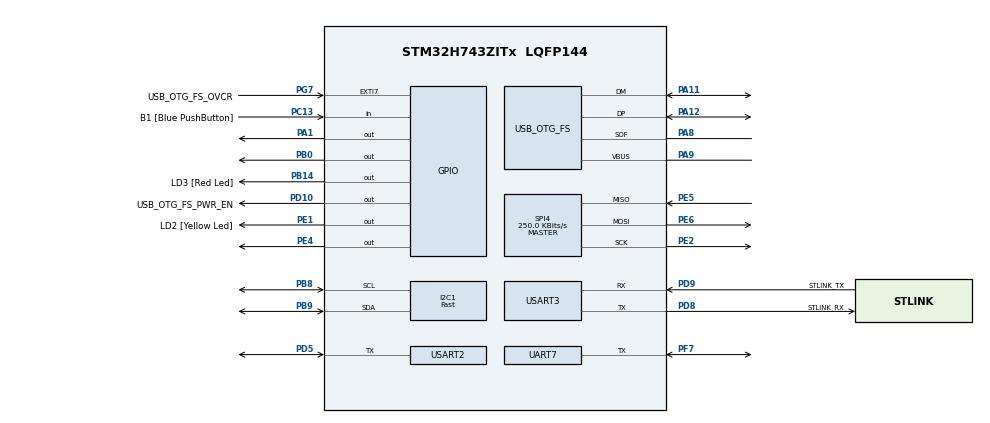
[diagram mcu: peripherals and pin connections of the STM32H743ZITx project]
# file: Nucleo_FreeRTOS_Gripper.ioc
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Dma.I2C1_RX.0.Direction=DMA_PERIPH_TO_MEMORY
Dma.I2C1_RX.0.EventEnable=DISABLE
Dma.I2C1_RX.0.FIFOMode=DMA_FIFOMODE_ENABLE
Dma.I2C1_RX.0.FIFOThreshold=DMA_FIFO_THRESHOLD_FULL
Dma.I2C1_RX.0.Instance=DMA1_Stream0
Dma.I2C1_RX.0.MemBurst=DMA_MBURST_INC16
Dma.I2C1_RX.0.MemDataAlignment=DMA_MDATAALIGN_BYTE
Dma.I2C1_RX.0.MemInc=DMA_MINC_ENABLE
Dma.I2C1_RX.0.Mode=DMA_NORMAL
Dma.I2C1_RX.0.PeriphBurst=DMA_PBURST_SINGLE
Dma.I2C1_RX.0.PeriphDataAlignment=DMA_PDATAALIGN_BYTE
Dma.I2C1_RX.0.PeriphInc=DMA_PINC_DISABLE
Dma.I2C1_RX.0.Polarity=HAL_DMAMUX_REQ_GEN_RISING
Dma.I2C1_RX.0.Priority=DMA_PRIORITY_HIGH
Dma.I2C1_RX.0.RequestNumber=1
Dma.I2C1_RX.0.SignalID=NONE
Dma.I2C1_RX.0.SyncEnable=DISABLE
Dma.I2C1_RX.0.SyncPolarity=HAL_DMAMUX_SYNC_NO_EVENT
Dma.I2C1_RX.0.SyncRequestNumber=1
Dma.I2C1_RX.0.SyncSignalID=NONE
Dma.Request0=I2C1_RX
FREERTOS.Tasks01=ControlTask,24,128,StartControlTask,Default,NULL,Dynamic,NULL,NULL;CommBoard,32,128,StartCommBoard,Default,NULL,Dynamic,NULL,NULL;SensorRead,8,128,StartSensorRead,Default,NULL,Dynamic,NULL,NULL;Safety,8,128,StartSafety,Default,NULL,Dynamic,NULL,NULL
I2C1.CustomTiming=Enabled
I2C1.I2C_Speed_Mode=I2C_Fast
I2C1.OwnAddress=0x5
I2C1.Timing=0x00602173
Mcu.Family=STM32H7
Mcu.Name=STM32H743ZITx
Mcu.Package=LQFP144
NVIC.DMA1_Stream0_IRQn=true\:0\:0\:false\:false\:true\:true\:false\:true
NVIC.PriorityGroup=NVIC_PRIORITYGROUP_4
NVIC.TIM6_DAC_IRQn=true\:0\:0\:false\:false\:true\:false\:false\:true
NVIC.TimeBase=TIM6_DAC_IRQn
NVIC.TimeBaseIP=TIM6
PA1.Signal=GPIO_Output
PA11.Mode=Device_Only
PA11.Signal=USB_OTG_FS_DM
PA12.Mode=Device_Only
PA12.Signal=USB_OTG_FS_DP
PA7.Signal=ETH_CRS_DV
PA8.Mode=Activate_SOF_FS
PA8.Signal=USB_OTG_FS_SOF
PA9.Mode=Activate_VBUS
PA9.Signal=USB_OTG_FS_VBUS
PB0.Signal=GPIO_Output
PB13.Signal=ETH_TXD1
PB14.GPIO_Label=LD3 [Red Led]
PB14.Signal=GPIO_Output
PB8.Mode=I2C
PB8.Signal=I2C1_SCL
PB9.Mode=I2C
PB9.Signal=I2C1_SDA
PC1.Signal=ETH_MDC
PC13.GPIO_Label=B1 [Blue PushButton]
PC13.Signal=GPIO_Input
PC14-OSC32_IN\ (OSC32_IN).Mode=LSE-External-Oscillator
PC14-OSC32_IN\ (OSC32_IN).Signal=RCC_OSC32_IN
PC15-OSC32_OUT\ (OSC32_OUT).Mode=LSE-External-Oscillator
PC15-OSC32_OUT\ (OSC32_OUT).Signal=RCC_OSC32_OUT
PC4.Signal=ETH_RXD0
PC5.Signal=ETH_RXD1
PD10.GPIO_Label=USB_OTG_FS_PWR_EN
PD10.Signal=GPIO_Output
PD5.Mode=Half_duplex(single_wire_mode)
PD5.Signal=USART2_TX
PD8.GPIO_Label=STLINK_RX
PD8.Mode=Asynchronous
PD8.Signal=USART3_TX
PD9.GPIO_Label=STLINK_TX
PD9.Mode=Asynchronous
PD9.Signal=USART3_RX
PE1.GPIO_Label=LD2 [Yellow Led]
PE1.Signal=GPIO_Output
PE2.Mode=Full_Duplex_Master
PE2.Signal=SPI4_SCK
PE4.Signal=GPIO_Output
PE5.Mode=Full_Duplex_Master
PE5.Signal=SPI4_MISO
PE6.Mode=Full_Duplex_Master
PE6.Signal=SPI4_MOSI
PF7.Mode=Half_duplex(single_wire_mode)
PF7.Signal=UART7_TX
PG11.Signal=ETH_TX_EN
PG13.Signal=ETH_TXD0
PG7.GPIO_Label=USB_OTG_FS_OVCR
PG7.Signal=GPXTI7
PH0-OSC_IN\ (PH0).Mode=HSE-External-Clock-Source
PH0-OSC_IN\ (PH0).Signal=RCC_OSC_IN
PH1-OSC_OUT\ (PH1).Signal=RCC_OSC_OUT
ProjectManager.HeapSize=0x200
ProjectManager.StackSize=0x400
ProjectManager.TargetToolchain=STM32CubeIDE
RCC.ADCFreq_Value=16125000
RCC.APB1Freq_Value=64000000
RCC.APB2Freq_Value=64000000
RCC.APB3Freq_Value=64000000
RCC.APB4Freq_Value=64000000
RCC.CortexFreq_Value=64000000
RCC.DIVM1=1
RCC.DIVN1=24
RCC.DIVQ1=4
RCC.HCLKFreq_Value=64000000
RCC.HSE_VALUE=8000000
RCC.PLLFRACN=0
RCC.SYSCLKFreq_VALUE=64000000
RCC.USBFreq_Value=48000000
SPI4.BaudRatePrescaler=SPI_BAUDRATEPRESCALER_256
SPI4.CLKPhase=SPI_PHASE_2EDGE
SPI4.CLKPolarity=SPI_POLARITY_HIGH
SPI4.CalculateBaudRate=250.0 KBits/s
SPI4.DataSize=SPI_DATASIZE_8BIT
SPI4.Direction=SPI_DIRECTION_2LINES
SPI4.Mode=SPI_MODE_MASTER
SPI4.NSSPMode=SPI_NSS_PULSE_DISABLE
SPI4.VirtualType=VM_MASTER
UART7.BaudRate=1000000
USART2.BaudRate=1000000
USART2.VirtualMode-Half_duplex(single_wire_mode)=VM_ASYNC
USART3.VirtualMode-Asynchronous=VM_ASYNC
USB_OTG_FS.VirtualMode=Device_Only
VP_FREERTOS_VS_CMSIS_V2.Mode=CMSIS_V2
VP_SYS_VS_tim6.Mode=TIM6
board=NUCLEO-H743ZI2

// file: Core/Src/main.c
/* USER CODE BEGIN Header */
/**
  ******************************************************************************
  * @file           : main.c
  * @brief          : Main program body
  ******************************************************************************
  * @attention
  *
  * <h2><center>&copy; Copyright (c) 2020 STMicroelectronics.
  * All rights reserved.</center></h2>
  *
  * This software component is licensed by ST under BSD 3-Clause license,
  * the "License"; You may not use this file except in compliance with the
  * License. You may obtain a copy of the License at:
  *                        opensource.org/licenses/BSD-3-Clause
  *
  ******************************************************************************
  */
/* USER CODE END Header */
#include "main.h"
#include "cmsis_os.h"

/* USER CODE BEGIN Includes */

#include<stdio.h>
#include <stdbool.h>

/* USER CODE END Includes */

/* USER CODE BEGIN PTD */

// Adress to nucleo board
#define NUCLEO_ADDRESS "0x5"

// The numbers of sensors
#define NUMBER_OF_MOTORS 8
#define NUMBER_OF_PROXIMITY_SENSORS 7
#define NUMBER_OF_MOUSE_SESNORS 4

/* USER CODE END PTD */

I2C_HandleTypeDef hi2c1;
DMA_HandleTypeDef hdma_i2c1_rx;

SPI_HandleTypeDef hspi4;

UART_HandleTypeDef huart7;
UART_HandleTypeDef huart2;
UART_HandleTypeDef huart3;

PCD_HandleTypeDef hpcd_USB_OTG_FS;

/* Definitions for ControlTask */
osThreadId_t ControlTaskHandle;
const osThreadAttr_t ControlTask_attributes = {
  .name = "ControlTask",
  .priority = (osPriority_t) osPriorityNormal,
  .stack_size = 128 * 4
};
/* Definitions for CommBoard */
osThreadId_t CommBoardHandle;
const osThreadAttr_t CommBoard_attributes = {
  .name = "CommBoard",
  .priority = (osPriority_t) osPriorityAboveNormal,
  .stack_size = 128 * 4
};
/* Definitions for SensorRead */
osThreadId_t SensorReadHandle;
const osThreadAttr_t SensorRead_attributes = {
  .name = "SensorRead",
  .priority = (osPriority_t) osPriorityLow,
  .stack_size = 128 * 4
};
/* Definitions for Safety */
osThreadId_t SafetyHandle;
const osThreadAttr_t Safety_attributes = {
  .name = "Safety",
  .priority = (osPriority_t) osPriorityLow,
  .stack_size = 128 * 4
};
/* USER CODE BEGIN PV */

const unsigned short firmware_length = 4094;

const uint8_t firmware_data[] = {    // SROM 0x04
0x01, 0x04, 0x8e, 0x96, 0x6e, 0x77, 0x3e, 0xfe, 0x7e, 0x5f, 0x1d, 0xb8, 0xf2, 0x66, 0x4e,
0xff, 0x5d, 0x19, 0xb0, 0xc2, 0x04, 0x69, 0x54, 0x2a, 0xd6, 0x2e, 0xbf, 0xdd, 0x19, 0xb0,
0xc3, 0xe5, 0x29, 0xb1, 0xe0, 0x23, 0xa5, 0xa9, 0xb1, 0xc1, 0x00, 0x82, 0x67, 0x4c, 0x1a,
0x97, 0x8d, 0x79, 0x51, 0x20, 0xc7, 0x06, 0x8e, 0x7c, 0x7c, 0x7a, 0x76, 0x4f, 0xfd, 0x59,
0x30, 0xe2, 0x46, 0x0e, 0x9e, 0xbe, 0xdf, 0x1d, 0x99, 0x91, 0xa0, 0xa5, 0xa1, 0xa9, 0xd0,
0x22, 0xc6, 0xef, 0x5c, 0x1b, 0x95, 0x89, 0x90, 0xa2, 0xa7, 0xcc, 0xfb, 0x55, 0x28, 0xb3,
0xe4, 0x4a, 0xf7, 0x6c, 0x3b, 0xf4, 0x6a, 0x56, 0x2e, 0xde, 0x1f, 0x9d, 0xb8, 0xd3, 0x05,
0x88, 0x92, 0xa6, 0xce, 0x1e, 0xbe, 0xdf, 0x1d, 0x99, 0xb0, 0xe2, 0x46, 0xef, 0x5c, 0x07,
0x11, 0x5d, 0x98, 0x0b, 0x9d, 0x94, 0x97, 0xee, 0x4e, 0x45, 0x33, 0x6b, 0x44, 0xc7, 0x29,
0x56, 0x27, 0x30, 0xc6, 0xa7, 0xd5, 0xf2, 0x56, 0xdf, 0xb4, 0x38, 0x62, 0xcb, 0xa0, 0xb6,
0xe3, 0x0f, 0x84, 0x06, 0x24, 0x05, 0x65, 0x6f, 0x76, 0x89, 0xb5, 0x77, 0x41, 0x27, 0x82,
0x66, 0x65, 0x82, 0xcc, 0xd5, 0xe6, 0x20, 0xd5, 0x27, 0x17, 0xc5, 0xf8, 0x03, 0x23, 0x7c,
0x5f, 0x64, 0xa5, 0x1d, 0xc1, 0xd6, 0x36, 0xcb, 0x4c, 0xd4, 0xdb, 0x66, 0xd7, 0x8b, 0xb1,
0x99, 0x7e, 0x6f, 0x4c, 0x36, 0x40, 0x06, 0xd6, 0xeb, 0xd7, 0xa2, 0xe4, 0xf4, 0x95, 0x51,
0x5a, 0x54, 0x96, 0xd5, 0x53, 0x44, 0xd7, 0x8c, 0xe0, 0xb9, 0x40, 0x68, 0xd2, 0x18, 0xe9,
0xdd, 0x9a, 0x23, 0x92, 0x48, 0xee, 0x7f, 0x43, 0xaf, 0xea, 0x77, 0x38, 0x84, 0x8c, 0x0a,
0x72, 0xaf, 0x69, 0xf8, 0xdd, 0xf1, 0x24, 0x83, 0xa3, 0xf8, 0x4a, 0xbf, 0xf5, 0x94, 0x13,
0xdb, 0xbb, 0xd8, 0xb4, 0xb3, 0xa0, 0xfb, 0x45, 0x50, 0x60, 0x30, 0x59, 0x12, 0x31, 0x71,
0xa2, 0xd3, 0x13, 0xe7, 0xfa, 0xe7, 0xce, 0x0f, 0x63, 0x15, 0x0b, 0x6b, 0x94, 0xbb, 0x37,
0x83, 0x26, 0x05, 0x9d, 0xfb, 0x46, 0x92, 0xfc, 0x0a, 0x15, 0xd1, 0x0d, 0x73, 0x92, 0xd6,
0x8c, 0x1b, 0x8c, 0xb8, 0x55, 0x8a, 0xce, 0xbd, 0xfe, 0x8e, 0xfc, 0xed, 0x09, 0x12, 0x83,
0x91, 0x82, 0x51, 0x31, 0x23, 0xfb, 0xb4, 0x0c, 0x76, 0xad, 0x7c, 0xd9, 0xb4, 0x4b, 0xb2,
0x67, 0x14, 0x09, 0x9c, 0x7f, 0x0c, 0x18, 0xba, 0x3b, 0xd6, 0x8e, 0x14, 0x2a, 0xe4, 0x1b,
0x52, 0x9f, 0x2b, 0x7d, 0xe1, 0xfb, 0x6a, 0x33, 0x02, 0xfa, 0xac, 0x5a, 0xf2, 0x3e, 0x88,
0x7e, 0xae, 0xd1, 0xf3, 0x78, 0xe8, 0x05, 0xd1, 0xe3, 0xdc, 0x21, 0xf6, 0xe1, 0x9a, 0xbd,
0x17, 0x0e, 0xd9, 0x46, 0x9b, 0x88, 0x03, 0xea, 0xf6, 0x66, 0xbe, 0x0e, 0x1b, 0x50, 0x49,
0x96, 0x40, 0x97, 0xf1, 0xf1, 0xe4, 0x80, 0xa6, 0x6e, 0xe8, 0x77, 0x34, 0xbf, 0x29, 0x40,
0x44, 0xc2, 0xff, 0x4e, 0x98, 0xd3, 0x9c, 0xa3, 0x32, 0x2b, 0x76, 0x51, 0x04, 0x09, 0xe7,
0xa9, 0xd1, 0xa6, 0x32, 0xb1, 0x23, 0x53, 0xe2, 0x47, 0xab, 0xd6, 0xf5, 0x69, 0x5c, 0x3e,
0x5f, 0xfa, 0xae, 0x45, 0x20, 0xe5, 0xd2, 0x44, 0xff, 0x39, 0x32, 0x6d, 0xfd, 0x27, 0x57,
0x5c, 0xfd, 0xf0, 0xde, 0xc1, 0xb5, 0x99, 0xe5, 0xf5, 0x1c, 0x77, 0x01, 0x75, 0xc5, 0x6d,
0x58, 0x92, 0xf2, 0xb2, 0x47, 0x00, 0x01, 0x26, 0x96, 0x7a, 0x30, 0xff, 0xb7, 0xf0, 0xef,
0x77, 0xc1, 0x8a, 0x5d, 0xdc, 0xc0, 0xd1, 0x29, 0x30, 0x1e, 0x77, 0x38, 0x7a, 0x94, 0xf1,
0xb8, 0x7a, 0x7e, 0xef, 0xa4, 0xd1, 0xac, 0x31, 0x4a, 0xf2, 0x5d, 0x64, 0x3d, 0xb2, 0xe2,
0xf0, 0x08, 0x99, 0xfc, 0x70, 0xee, 0x24, 0xa7, 0x7e, 0xee, 0x1e, 0x20, 0x69, 0x7d, 0x44,
0xbf, 0x87, 0x42, 0xdf, 0x88, 0x3b, 0x0c, 0xda, 0x42, 0xc9, 0x04, 0xf9, 0x45, 0x50, 0xfc,
0x83, 0x8f, 0x11, 0x6a, 0x72, 0xbc, 0x99, 0x95, 0xf0, 0xac, 0x3d, 0xa7, 0x3b, 0xcd, 0x1c,
0xe2, 0x88, 0x79, 0x37, 0x11, 0x5f, 0x39, 0x89, 0x95, 0x0a, 0x16, 0x84, 0x7a, 0xf6, 0x8a,
0xa4, 0x28, 0xe4, 0xed, 0x83, 0x80, 0x3b, 0xb1, 0x23, 0xa5, 0x03, 0x10, 0xf4, 0x66, 0xea,
0xbb, 0x0c, 0x0f, 0xc5, 0xec, 0x6c, 0x69, 0xc5, 0xd3, 0x24, 0xab, 0xd4, 0x2a, 0xb7, 0x99,
0x88, 0x76, 0x08, 0xa0, 0xa8, 0x95, 0x7c, 0xd8, 0x38, 0x6d, 0xcd, 0x59, 0x02, 0x51, 0x4b,
0xf1, 0xb5, 0x2b, 0x50, 0xe3, 0xb6, 0xbd, 0xd0, 0x72, 0xcf, 0x9e, 0xfd, 0x6e, 0xbb, 0x44,
0xc8, 0x24, 0x8a, 0x77, 0x18, 0x8a, 0x13, 0x06, 0xef, 0x97, 0x7d, 0xfa, 0x81, 0xf0, 0x31,
0xe6, 0xfa, 0x77, 0xed, 0x31, 0x06, 0x31, 0x5b, 0x54, 0x8a, 0x9f, 0x30, 0x68, 0xdb, 0xe2,
0x40, 0xf8, 0x4e, 0x73, 0xfa, 0xab, 0x74, 0x8b, 0x10, 0x58, 0x13, 0xdc, 0xd2, 0xe6, 0x78,
0xd1, 0x32, 0x2e, 0x8a, 0x9f, 0x2c, 0x58, 0x06, 0x48, 0x27, 0xc5, 0xa9, 0x5e, 0x81, 0x47,
0x89, 0x46, 0x21, 0x91, 0x03, 0x70, 0xa4, 0x3e, 0x88, 0x9c, 0xda, 0x33, 0x0a, 0xce, 0xbc,
0x8b, 0x8e, 0xcf, 0x9f, 0xd3, 0x71, 0x80, 0x43, 0xcf, 0x6b, 0xa9, 0x51, 0x83, 0x76, 0x30,
0x82, 0xc5, 0x6a, 0x85, 0x39, 0x11, 0x50, 0x1a, 0x82, 0xdc, 0x1e, 0x1c, 0xd5, 0x7d, 0xa9,
0x71, 0x99, 0x33, 0x47, 0x19, 0x97, 0xb3, 0x5a, 0xb1, 0xdf, 0xed, 0xa4, 0xf2, 0xe6, 0x26,
0x84, 0xa2, 0x28, 0x9a, 0x9e, 0xdf, 0xa6, 0x6a, 0xf4, 0xd6, 0xfc, 0x2e, 0x5b, 0x9d, 0x1a,
0x2a, 0x27, 0x68, 0xfb, 0xc1, 0x83, 0x21, 0x4b, 0x90, 0xe0, 0x36, 0xdd, 0x5b, 0x31, 0x42,
0x55, 0xa0, 0x13, 0xf7, 0xd0, 0x89, 0x53, 0x71, 0x99, 0x57, 0x09, 0x29, 0xc5, 0xf3, 0x21,
0xf8, 0x37, 0x2f, 0x40, 0xf3, 0xd4, 0xaf, 0x16, 0x08, 0x36, 0x02, 0xfc, 0x77, 0xc5, 0x8b,
0x04, 0x90, 0x56, 0xb9, 0xc9, 0x67, 0x9a, 0x99, 0xe8, 0x00, 0xd3, 0x86, 0xff, 0x97, 0x2d,
0x08, 0xe9, 0xb7, 0xb3, 0x91, 0xbc, 0xdf, 0x45, 0xc6, 0xed, 0x0f, 0x8c, 0x4c, 0x1e, 0xe6,
0x5b, 0x6e, 0x38, 0x30, 0xe4, 0xaa, 0xe3, 0x95, 0xde, 0xb9, 0xe4, 0x9a, 0xf5, 0xb2, 0x55,
0x9a, 0x87, 0x9b, 0xf6, 0x6a, 0xb2, 0xf2, 0x77, 0x9a, 0x31, 0xf4, 0x7a, 0x31, 0xd1, 0x1d,
0x04, 0xc0, 0x7c, 0x32, 0xa2, 0x9e, 0x9a, 0xf5, 0x62, 0xf8, 0x27, 0x8d, 0xbf, 0x51, 0xff,
0xd3, 0xdf, 0x64, 0x37, 0x3f, 0x2a, 0x6f, 0x76, 0x3a, 0x7d, 0x77, 0x06, 0x9e, 0x77, 0x7f,
0x5e, 0xeb, 0x32, 0x51, 0xf9, 0x16, 0x66, 0x9a, 0x09, 0xf3, 0xb0, 0x08, 0xa4, 0x70, 0x96,
0x46, 0x30, 0xff, 0xda, 0x4f, 0xe9, 0x1b, 0xed, 0x8d, 0xf8, 0x74, 0x1f, 0x31, 0x92, 0xb3,
0x73, 0x17, 0x36, 0xdb, 0x91, 0x30, 0xd6, 0x88, 0x55, 0x6b, 0x34, 0x77, 0x87, 0x7a, 0xe7,
0xee, 0x06, 0xc6, 0x1c, 0x8c, 0x19, 0x0c, 0x48, 0x46, 0x23, 0x5e, 0x9c, 0x07, 0x5c, 0xbf,
0xb4, 0x7e, 0xd6, 0x4f, 0x74, 0x9c, 0xe2, 0xc5, 0x50, 0x8b, 0xc5, 0x8b, 0x15, 0x90, 0x60,
0x62, 0x57, 0x29, 0xd0, 0x13, 0x43, 0xa1, 0x80, 0x88, 0x91, 0x00, 0x44, 0xc7, 0x4d, 0x19,
0x86, 0xcc, 0x2f, 0x2a, 0x75, 0x5a, 0xfc, 0xeb, 0x97, 0x2a, 0x70, 0xe3, 0x78, 0xd8, 0x91,
0xb0, 0x4f, 0x99, 0x07, 0xa3, 0x95, 0xea, 0x24, 0x21, 0xd5, 0xde, 0x51, 0x20, 0x93, 0x27,
0x0a, 0x30, 0x73, 0xa8, 0xff, 0x8a, 0x97, 0xe9, 0xa7, 0x6a, 0x8e, 0x0d, 0xe8, 0xf0, 0xdf,
0xec, 0xea, 0xb4, 0x6c, 0x1d, 0x39, 0x2a, 0x62, 0x2d, 0x3d, 0x5a, 0x8b, 0x65, 0xf8, 0x90,
0x05, 0x2e, 0x7e, 0x91, 0x2c, 0x78, 0xef, 0x8e, 0x7a, 0xc1, 0x2f, 0xac, 0x78, 0xee, 0xaf,
0x28, 0x45, 0x06, 0x4c, 0x26, 0xaf, 0x3b, 0xa2, 0xdb, 0xa3, 0x93, 0x06, 0xb5, 0x3c, 0xa5,
0xd8, 0xee, 0x8f, 0xaf, 0x25, 0xcc, 0x3f, 0x85, 0x68, 0x48, 0xa9, 0x62, 0xcc, 0x97, 0x8f,
0x7f, 0x2a, 0xea, 0xe0, 0x15, 0x0a, 0xad, 0x62, 0x07, 0xbd, 0x45, 0xf8, 0x41, 0xd8, 0x36,
0xcb, 0x4c, 0xdb, 0x6e, 0xe6, 0x3a, 0xe7, 0xda, 0x15, 0xe9, 0x29, 0x1e, 0x12, 0x10, 0xa0,
0x14, 0x2c, 0x0e, 0x3d, 0xf4, 0xbf, 0x39, 0x41, 0x92, 0x75, 0x0b, 0x25, 0x7b, 0xa3, 0xce,
0x39, 0x9c, 0x15, 0x64, 0xc8, 0xfa, 0x3d, 0xef, 0x73, 0x27, 0xfe, 0x26, 0x2e, 0xce, 0xda,
0x6e, 0xfd, 0x71, 0x8e, 0xdd, 0xfe, 0x76, 0xee, 0xdc, 0x12, 0x5c, 0x02, 0xc5, 0x3a, 0x4e,
0x4e, 0x4f, 0xbf, 0xca, 0x40, 0x15, 0xc7, 0x6e, 0x8d, 0x41, 0xf1, 0x10, 0xe0, 0x4f, 0x7e,
0x97, 0x7f, 0x1c, 0xae, 0x47, 0x8e, 0x6b, 0xb1, 0x25, 0x31, 0xb0, 0x73, 0xc7, 0x1b, 0x97,
0x79, 0xf9, 0x80, 0xd3, 0x66, 0x22, 0x30, 0x07, 0x74, 0x1e, 0xe4, 0xd0, 0x80, 0x21, 0xd6,
0xee, 0x6b, 0x6c, 0x4f, 0xbf, 0xf5, 0xb7, 0xd9, 0x09, 0x87, 0x2f, 0xa9, 0x14, 0xbe, 0x27,
0xd9, 0x72, 0x50, 0x01, 0xd4, 0x13, 0x73, 0xa6, 0xa7, 0x51, 0x02, 0x75, 0x25, 0xe1, 0xb3,
0x45, 0x34, 0x7d, 0xa8, 0x8e, 0xeb, 0xf3, 0x16, 0x49, 0xcb, 0x4f, 0x8c, 0xa1, 0xb9, 0x36,
0x85, 0x39, 0x75, 0x5d, 0x08, 0x00, 0xae, 0xeb, 0xf6, 0xea, 0xd7, 0x13, 0x3a, 0x21, 0x5a,
0x5f, 0x30, 0x84, 0x52, 0x26, 0x95, 0xc9, 0x14, 0xf2, 0x57, 0x55, 0x6b, 0xb1, 0x10, 0xc2,
0xe1, 0xbd, 0x3b, 0x51, 0xc0, 0xb7, 0x55, 0x4c, 0x71, 0x12, 0x26, 0xc7, 0x0d, 0xf9, 0x51,
0xa4, 0x38, 0x02, 0x05, 0x7f, 0xb8, 0xf1, 0x72, 0x4b, 0xbf, 0x71, 0x89, 0x14, 0xf3, 0x77,
0x38, 0xd9, 0x71, 0x24, 0xf3, 0x00, 0x11, 0xa1, 0xd8, 0xd4, 0x69, 0x27, 0x08, 0x37, 0x35,
0xc9, 0x11, 0x9d, 0x90, 0x1c, 0x0e, 0xe7, 0x1c, 0xff, 0x2d, 0x1e, 0xe8, 0x92, 0xe1, 0x18,
0x10, 0x95, 0x7c, 0xe0, 0x80, 0xf4, 0x96, 0x43, 0x21, 0xf9, 0x75, 0x21, 0x64, 0x38, 0xdd,
0x9f, 0x1e, 0x95, 0x16, 0xda, 0x56, 0x1d, 0x4f, 0x9a, 0x53, 0xb2, 0xe2, 0xe4, 0x18, 0xcb,
0x6b, 0x1a, 0x65, 0xeb, 0x56, 0xc6, 0x3b, 0xe5, 0xfe, 0xd8, 0x26, 0x3f, 0x3a, 0x84, 0x59,
0x72, 0x66, 0xa2, 0xf3, 0x75, 0xff, 0xfb, 0x60, 0xb3, 0x22, 0xad, 0x3f, 0x2d, 0x6b, 0xf9,
0xeb, 0xea, 0x05, 0x7c, 0xd8, 0x8f, 0x6d, 0x2c, 0x98, 0x9e, 0x2b, 0x93, 0xf1, 0x5e, 0x46,
0xf0, 0x87, 0x49, 0x29, 0x73, 0x68, 0xd7, 0x7f, 0xf9, 0xf0, 0xe5, 0x7d, 0xdb, 0x1d, 0x75,
0x19, 0xf3, 0xc4, 0x58, 0x9b, 0x17, 0x88, 0xa8, 0x92, 0xe0, 0xbe, 0xbd, 0x8b, 0x1d, 0x8d,
0x9f, 0x56, 0x76, 0xad, 0xaf, 0x29, 0xe2, 0xd9, 0xd5, 0x52, 0xf6, 0xb5, 0x56, 0x35, 0x57,
0x3a, 0xc8, 0xe1, 0x56, 0x43, 0x19, 0x94, 0xd3, 0x04, 0x9b, 0x6d, 0x35, 0xd8, 0x0b, 0x5f,
0x4d, 0x19, 0x8e, 0xec, 0xfa, 0x64, 0x91, 0x0a, 0x72, 0x20, 0x2b, 0xbc, 0x1a, 0x4a, 0xfe,
0x8b, 0xfd, 0xbb, 0xed, 0x1b, 0x23, 0xea, 0xad, 0x72, 0x82, 0xa1, 0x29, 0x99, 0x71, 0xbd,
0xf0, 0x95, 0xc1, 0x03, 0xdd, 0x7b, 0xc2, 0xb2, 0x3c, 0x28, 0x54, 0xd3, 0x68, 0xa4, 0x72,
0xc8, 0x66, 0x96, 0xe0, 0xd1, 0xd8, 0x7f, 0xf8, 0xd1, 0x26, 0x2b, 0xf7, 0xad, 0xba, 0x55,
0xca, 0x15, 0xb9, 0x32, 0xc3, 0xe5, 0x88, 0x97, 0x8e, 0x5c, 0xfb, 0x92, 0x25, 0x8b, 0xbf,
0xa2, 0x45, 0x55, 0x7a, 0xa7, 0x6f, 0x8b, 0x57, 0x5b, 0xcf, 0x0e, 0xcb, 0x1d, 0xfb, 0x20,
0x82, 0x77, 0xa8, 0x8c, 0xcc, 0x16, 0xce, 0x1d, 0xfa, 0xde, 0xcc, 0x0b, 0x62, 0xfe, 0xcc,
0xe1, 0xb7, 0xf0, 0xc3, 0x81, 0x64, 0x73, 0x40, 0xa0, 0xc2, 0x4d, 0x89, 0x11, 0x75, 0x33,
0x55, 0x33, 0x8d, 0xe8, 0x4a, 0xfd, 0xea, 0x6e, 0x30, 0x0b, 0xd7, 0x31, 0x2c, 0xde, 0x47,
0xe3, 0xbf, 0xf8, 0x55, 0x42, 0xe2, 0x7f, 0x59, 0xe5, 0x17, 0xef, 0x99, 0x34, 0x69, 0x91,
0xb1, 0x23, 0x8e, 0x20, 0x87, 0x2d, 0xa8, 0xfe, 0xd5, 0x8a, 0xf3, 0x84, 0x3a, 0xf0, 0x37,
0xe4, 0x09, 0x00, 0x54, 0xee, 0x67, 0x49, 0x93, 0xe4, 0x81, 0x70, 0xe3, 0x90, 0x4d, 0xef,
0xfe, 0x41, 0xb7, 0x99, 0x7b, 0xc1, 0x83, 0xba, 0x62, 0x12, 0x6f, 0x7d, 0xde, 0x6b, 0xaf,
0xda, 0x16, 0xf9, 0x55, 0x51, 0xee, 0xa6, 0x0c, 0x2b, 0x02, 0xa3, 0xfd, 0x8d, 0xfb, 0x30,
0x17, 0xe4, 0x6f, 0xdf, 0x36, 0x71, 0xc4, 0xca, 0x87, 0x25, 0x48, 0xb0, 0x47, 0xec, 0xea,
0xb4, 0xbf, 0xa5, 0x4d, 0x9b, 0x9f, 0x02, 0x93, 0xc4, 0xe3, 0xe4, 0xe8, 0x42, 0x2d, 0x68,
0x81, 0x15, 0x0a, 0xeb, 0x84, 0x5b, 0xd6, 0xa8, 0x74, 0xfb, 0x7d, 0x1d, 0xcb, 0x2c, 0xda,
0x46, 0x2a, 0x76, 0x62, 0xce, 0xbc, 0x5c, 0x9e, 0x8b, 0xe7, 0xcf, 0xbe, 0x78, 0xf5, 0x7c,
0xeb, 0xb3, 0x3a, 0x9c, 0xaa, 0x6f, 0xcc, 0x72, 0xd1, 0x59, 0xf2, 0x11, 0x23, 0xd6, 0x3f,
0x48, 0xd1, 0xb7, 0xce, 0xb0, 0xbf, 0xcb, 0xea, 0x80, 0xde, 0x57, 0xd4, 0x5e, 0x97, 0x2f,
0x75, 0xd1, 0x50, 0x8e, 0x80, 0x2c, 0x66, 0x79, 0xbf, 0x72, 0x4b, 0xbd, 0x8a, 0x81, 0x6c,
0xd3, 0xe1, 0x01, 0xdc, 0xd2, 0x15, 0x26, 0xc5, 0x36, 0xda, 0x2c, 0x1a, 0xc0, 0x27, 0x94,
0xed, 0xb7, 0x9b, 0x85, 0x0b, 0x5e, 0x80, 0x97, 0xc5, 0xec, 0x4f, 0xec, 0x88, 0x5d, 0x50,
0x07, 0x35, 0x47, 0xdc, 0x0b, 0x3b, 0x3d, 0xdd, 0x60, 0xaf, 0xa8, 0x5d, 0x81, 0x38, 0x24,
0x25, 0x5d, 0x5c, 0x15, 0xd1, 0xde, 0xb3, 0xab, 0xec, 0x05, 0x69, 0xef, 0x83, 0xed, 0x57,
0x54, 0xb8, 0x64, 0x64, 0x11, 0x16, 0x32, 0x69, 0xda, 0x9f, 0x2d, 0x7f, 0x36, 0xbb, 0x44,
0x5a, 0x34, 0xe8, 0x7f, 0xbf, 0x03, 0xeb, 0x00, 0x7f, 0x59, 0x68, 0x22, 0x79, 0xcf, 0x73,
0x6c, 0x2c, 0x29, 0xa7, 0xa1, 0x5f, 0x38, 0xa1, 0x1d, 0xf0, 0x20, 0x53, 0xe0, 0x1a, 0x63,
0x14, 0x58, 0x71, 0x10, 0xaa, 0x08, 0x0c, 0x3e, 0x16, 0x1a, 0x60, 0x22, 0x82, 0x7f, 0xba,
0xa4, 0x43, 0xa0, 0xd0, 0xac, 0x1b, 0xd5, 0x6b, 0x64, 0xb5, 0x14, 0x93, 0x31, 0x9e, 0x53,
0x50, 0xd0, 0x57, 0x66, 0xee, 0x5a, 0x4f, 0xfb, 0x03, 0x2a, 0x69, 0x58, 0x76, 0xf1, 0x83,
0xf7, 0x4e, 0xba, 0x8c, 0x42, 0x06, 0x60, 0x5d, 0x6d, 0xce, 0x60, 0x88, 0xae, 0xa4, 0xc3,
0xf1, 0x03, 0xa5, 0x4b, 0x98, 0xa1, 0xff, 0x67, 0xe1, 0xac, 0xa2, 0xb8, 0x62, 0xd7, 0x6f,
0xa0, 0x31, 0xb4, 0xd2, 0x77, 0xaf, 0x21, 0x10, 0x06, 0xc6, 0x9a, 0xff, 0x1d, 0x09, 0x17,
0x0e, 0x5f, 0xf1, 0xaa, 0x54, 0x34, 0x4b, 0x45, 0x8a, 0x87, 0x63, 0xa6, 0xdc, 0xf9, 0x24,
0x30, 0x67, 0xc6, 0xb2, 0xd6, 0x61, 0x33, 0x69, 0xee, 0x50, 0x61, 0x57, 0x28, 0xe7, 0x7e,
0xee, 0xec, 0x3a, 0x5a, 0x73, 0x4e, 0xa8, 0x8d, 0xe4, 0x18, 0xea, 0xec, 0x41, 0x64, 0xc8,
0xe2, 0xe8, 0x66, 0xb6, 0x2d, 0xb6, 0xfb, 0x6a, 0x6c, 0x16, 0xb3, 0xdd, 0x46, 0x43, 0xb9,
0x73, 0x00, 0x6a, 0x71, 0xed, 0x4e, 0x9d, 0x25, 0x1a, 0xc3, 0x3c, 0x4a, 0x95, 0x15, 0x99,
0x35, 0x81, 0x14, 0x02, 0xd6, 0x98, 0x9b, 0xec, 0xd8, 0x23, 0x3b, 0x84, 0x29, 0xaf, 0x0c,
0x99, 0x83, 0xa6, 0x9a, 0x34, 0x4f, 0xfa, 0xe8, 0xd0, 0x3c, 0x4b, 0xd0, 0xfb, 0xb6, 0x68,
0xb8, 0x9e, 0x8f, 0xcd, 0xf7, 0x60, 0x2d, 0x7a, 0x22, 0xe5, 0x7d, 0xab, 0x65, 0x1b, 0x95,
0xa7, 0xa8, 0x7f, 0xb6, 0x77, 0x47, 0x7b, 0x5f, 0x8b, 0x12, 0x72, 0xd0, 0xd4, 0x91, 0xef,
0xde, 0x19, 0x50, 0x3c, 0xa7, 0x8b, 0xc4, 0xa9, 0xb3, 0x23, 0xcb, 0x76, 0xe6, 0x81, 0xf0,
0xc1, 0x04, 0x8f, 0xa3, 0xb8, 0x54, 0x5b, 0x97, 0xac, 0x19, 0xff, 0x3f, 0x55, 0x27, 0x2f,
0xe0, 0x1d, 0x42, 0x9b, 0x57, 0xfc, 0x4b, 0x4e, 0x0f, 0xce, 0x98, 0xa9, 0x43, 0x57, 0x03,
0xbd, 0xe7, 0xc8, 0x94, 0xdf, 0x6e, 0x36, 0x73, 0x32, 0xb4, 0xef, 0x2e, 0x85, 0x7a, 0x6e,
0xfc, 0x6c, 0x18, 0x82, 0x75, 0x35, 0x90, 0x07, 0xf3, 0xe4, 0x9f, 0x3e, 0xdc, 0x68, 0xf3,
0xb5, 0xf3, 0x19, 0x80, 0x92, 0x06, 0x99, 0xa2, 0xe8, 0x6f, 0xff, 0x2e, 0x7f, 0xae, 0x42,
0xa4, 0x5f, 0xfb, 0xd4, 0x0e, 0x81, 0x2b, 0xc3, 0x04, 0xff, 0x2b, 0xb3, 0x74, 0x4e, 0x36,
0x5b, 0x9c, 0x15, 0x00, 0xc6, 0x47, 0x2b, 0xe8, 0x8b, 0x3d, 0xf1, 0x9c, 0x03, 0x9a, 0x58,
0x7f, 0x9b, 0x9c, 0xbf, 0x85, 0x49, 0x79, 0x35, 0x2e, 0x56, 0x7b, 0x41, 0x14, 0x39, 0x47,
0x83, 0x26, 0xaa, 0x07, 0x89, 0x98, 0x11, 0x1b, 0x86, 0xe7, 0x73, 0x7a, 0xd8, 0x7d, 0x78,
0x61, 0x53, 0xe9, 0x79, 0xf5, 0x36, 0x8d, 0x44, 0x92, 0x84, 0xf9, 0x13, 0x50, 0x58, 0x3b,
0xa4, 0x6a, 0x36, 0x65, 0x49, 0x8e, 0x3c, 0x0e, 0xf1, 0x6f, 0xd2, 0x84, 0xc4, 0x7e, 0x8e,
0x3f, 0x39, 0xae, 0x7c, 0x84, 0xf1, 0x63, 0x37, 0x8e, 0x3c, 0xcc, 0x3e, 0x44, 0x81, 0x45,
0xf1, 0x4b, 0xb9, 0xed, 0x6b, 0x36, 0x5d, 0xbb, 0x20, 0x60, 0x1a, 0x0f, 0xa3, 0xaa, 0x55,
0x77, 0x3a, 0xa9, 0xae, 0x37, 0x4d, 0xba, 0xb8, 0x86, 0x6b, 0xbc, 0x08, 0x50, 0xf6, 0xcc,
0xa4, 0xbd, 0x1d, 0x40, 0x72, 0xa5, 0x86, 0xfa, 0xe2, 0x10, 0xae, 0x3d, 0x58, 0x4b, 0x97,
0xf3, 0x43, 0x74, 0xa9, 0x9e, 0xeb, 0x21, 0xb7, 0x01, 0xa4, 0x86, 0x93, 0x97, 0xee, 0x2f,
0x4f, 0x3b, 0x86, 0xa1, 0x41, 0x6f, 0x41, 0x26, 0x90, 0x78, 0x5c, 0x7f, 0x30, 0x38, 0x4b,
0x3f, 0xaa, 0xec, 0xed, 0x5c, 0x6f, 0x0e, 0xad, 0x43, 0x87, 0xfd, 0x93, 0x35, 0xe6, 0x01,
0xef, 0x41, 0x26, 0x90, 0x99, 0x9e, 0xfb, 0x19, 0x5b, 0xad, 0xd2, 0x91, 0x8a, 0xe0, 0x46,
0xaf, 0x65, 0xfa, 0x4f, 0x84, 0xc1, 0xa1, 0x2d, 0xcf, 0x45, 0x8b, 0xd3, 0x85, 0x50, 0x55,
0x7c, 0xf9, 0x67, 0x88, 0xd4, 0x4e, 0xe9, 0xd7, 0x6b, 0x61, 0x54, 0xa1, 0xa4, 0xa6, 0xa2,
0xc2, 0xbf, 0x30, 0x9c, 0x40, 0x9f, 0x5f, 0xd7, 0x69, 0x2b, 0x24, 0x82, 0x5e, 0xd9, 0xd6,
0xa7, 0x12, 0x54, 0x1a, 0xf7, 0x55, 0x9f, 0x76, 0x50, 0xa9, 0x95, 0x84, 0xe6, 0x6b, 0x6d,
0xb5, 0x96, 0x54, 0xd6, 0xcd, 0xb3, 0xa1, 0x9b, 0x46, 0xa7, 0x94, 0x4d, 0xc4, 0x94, 0xb4,
0x98, 0xe3, 0xe1, 0xe2, 0x34, 0xd5, 0x33, 0x16, 0x07, 0x54, 0xcd, 0xb7, 0x77, 0x53, 0xdb,
0x4f, 0x4d, 0x46, 0x9d, 0xe9, 0xd4, 0x9c, 0x8a, 0x36, 0xb6, 0xb8, 0x38, 0x26, 0x6c, 0x0e,
0xff, 0x9c, 0x1b, 0x43, 0x8b, 0x80, 0xcc, 0xb9, 0x3d, 0xda, 0xc7, 0xf1, 0x8a, 0xf2, 0x6d,
0xb8, 0xd7, 0x74, 0x2f, 0x7e, 0x1e, 0xb7, 0xd3, 0x4a, 0xb4, 0xac, 0xfc, 0x79, 0x48, 0x6c,
0xbc, 0x96, 0xb6, 0x94, 0x46, 0x57, 0x2d, 0xb0, 0xa3, 0xfc, 0x1e, 0xb9, 0x52, 0x60, 0x85,
0x2d, 0x41, 0xd0, 0x43, 0x01, 0x1e, 0x1c, 0xd5, 0x7d, 0xfc, 0xf3, 0x96, 0x0d, 0xc7, 0xcb,
0x2a, 0x29, 0x9a, 0x93, 0xdd, 0x88, 0x2d, 0x37, 0x5d, 0xaa, 0xfb, 0x49, 0x68, 0xa0, 0x9c,
0x50, 0x86, 0x7f, 0x68, 0x56, 0x57, 0xf9, 0x79, 0x18, 0x39, 0xd4, 0xe0, 0x01, 0x84, 0x33,
0x61, 0xca, 0xa5, 0xd2, 0xd6, 0xe4, 0xc9, 0x8a, 0x4a, 0x23, 0x44, 0x4e, 0xbc, 0xf0, 0xdc,
0x24, 0xa1, 0xa0, 0xc4, 0xe2, 0x07, 0x3c, 0x10, 0xc4, 0xb5, 0x25, 0x4b, 0x65, 0x63, 0xf4,
0x80, 0xe7, 0xcf, 0x61, 0xb1, 0x71, 0x82, 0x21, 0x87, 0x2c, 0xf5, 0x91, 0x00, 0x32, 0x0c,
0xec, 0xa9, 0xb5, 0x9a, 0x74, 0x85, 0xe3, 0x36, 0x8f, 0x76, 0x4f, 0x9c, 0x6d, 0xce, 0xbc,
0xad, 0x0a, 0x4b, 0xed, 0x76, 0x04, 0xcb, 0xc3, 0xb9, 0x33, 0x9e, 0x01, 0x93, 0x96, 0x69,
0x7d, 0xc5, 0xa2, 0x45, 0x79, 0x9b, 0x04, 0x5c, 0x84, 0x09, 0xed, 0x88, 0x43, 0xc7, 0xab,
0x93, 0x14, 0x26, 0xa1, 0x40, 0xb5, 0xce, 0x4e, 0xbf, 0x2a, 0x42, 0x85, 0x3e, 0x2c, 0x3b,
0x54, 0xe8, 0x12, 0x1f, 0x0e, 0x97, 0x59, 0xb2, 0x27, 0x89, 0xfa, 0xf2, 0xdf, 0x8e, 0x68,
0x59, 0xdc, 0x06, 0xbc, 0xb6, 0x85, 0x0d, 0x06, 0x22, 0xec, 0xb1, 0xcb, 0xe5, 0x04, 0xe6,
0x3d, 0xb3, 0xb0, 0x41, 0x73, 0x08, 0x3f, 0x3c, 0x58, 0x86, 0x63, 0xeb, 0x50, 0xee, 0x1d,
0x2c, 0x37, 0x74, 0xa9, 0xd3, 0x18, 0xa3, 0x47, 0x6e, 0x93, 0x54, 0xad, 0x0a, 0x5d, 0xb8,
0x2a, 0x55, 0x5d, 0x78, 0xf6, 0xee, 0xbe, 0x8e, 0x3c, 0x76, 0x69, 0xb9, 0x40, 0xc2, 0x34,
0xec, 0x2a, 0xb9, 0xed, 0x7e, 0x20, 0xe4, 0x8d, 0x00, 0x38, 0xc7, 0xe6, 0x8f, 0x44, 0xa8,
0x86, 0xce, 0xeb, 0x2a, 0xe9, 0x90, 0xf1, 0x4c, 0xdf, 0x32, 0xfb, 0x73, 0x1b, 0x6d, 0x92,
0x1e, 0x95, 0xfe, 0xb4, 0xdb, 0x65, 0xdf, 0x4d, 0x23, 0x54, 0x89, 0x48, 0xbf, 0x4a, 0x2e,
0x70, 0xd6, 0xd7, 0x62, 0xb4, 0x33, 0x29, 0xb1, 0x3a, 0x33, 0x4c, 0x23, 0x6d, 0xa6, 0x76,
0xa5, 0x21, 0x63, 0x48, 0xe6, 0x90, 0x5d, 0xed, 0x90, 0x95, 0x0b, 0x7a, 0x84, 0xbe, 0xb8,
0x0d, 0x5e, 0x63, 0x0c, 0x62, 0x26, 0x4c, 0x14, 0x5a, 0xb3, 0xac, 0x23, 0xa4, 0x74, 0xa7,
0x6f, 0x33, 0x30, 0x05, 0x60, 0x01, 0x42, 0xa0, 0x28, 0xb7, 0xee, 0x19, 0x38, 0xf1, 0x64,
0x80, 0x82, 0x43, 0xe1, 0x41, 0x27, 0x1f, 0x1f, 0x90, 0x54, 0x7a, 0xd5, 0x23, 0x2e, 0xd1,
0x3d, 0xcb, 0x28, 0xba, 0x58, 0x7f, 0xdc, 0x7c, 0x91, 0x24, 0xe9, 0x28, 0x51, 0x83, 0x6e,
0xc5, 0x56, 0x21, 0x42, 0xed, 0xa0, 0x56, 0x22, 0xa1, 0x40, 0x80, 0x6b, 0xa8, 0xf7, 0x94,
0xca, 0x13, 0x6b, 0x0c, 0x39, 0xd9, 0xfd, 0xe9, 0xf3, 0x6f, 0xa6, 0x9e, 0xfc, 0x70, 0x8a,
0xb3, 0xbc, 0x59, 0x3c, 0x1e, 0x1d, 0x6c, 0xf9, 0x7c, 0xaf, 0xf9, 0x88, 0x71, 0x95, 0xeb,
0x57, 0x00, 0xbd, 0x9f, 0x8c, 0x4f, 0xe1, 0x24, 0x83, 0xc5, 0x22, 0xea, 0xfd, 0xd3, 0x0c,
0xe2, 0x17, 0x18, 0x7c, 0x6a, 0x4c, 0xde, 0x77, 0xb4, 0x53, 0x9b, 0x4c, 0x81, 0xcd, 0x23,
0x60, 0xaa, 0x0e, 0x25, 0x73, 0x9c, 0x02, 0x79, 0x32, 0x30, 0xdf, 0x74, 0xdf, 0x75, 0x19,
0xf4, 0xa5, 0x14, 0x5c, 0xf7, 0x7a, 0xa8, 0xa5, 0x91, 0x84, 0x7c, 0x60, 0x03, 0x06, 0x3b,
0xcd, 0x50, 0xb6, 0x27, 0x9c, 0xfe, 0xb1, 0xdd, 0xcc, 0xd3, 0xb0, 0x59, 0x24, 0xb2, 0xca,
0xe2, 0x1c, 0x81, 0x22, 0x9d, 0x07, 0x8f, 0x8e, 0xb9, 0xbe, 0x4e, 0xfa, 0xfc, 0x39, 0x65,
0xba, 0xbf, 0x9d, 0x12, 0x37, 0x5e, 0x97, 0x7e, 0xf3, 0x89, 0xf5, 0x5d, 0xf5, 0xe3, 0x09,
0x8c, 0x62, 0xb5, 0x20, 0x9d, 0x0c, 0x53, 0x8a, 0x68, 0x1b, 0xd2, 0x8f, 0x75, 0x17, 0x5d,
0xd4, 0xe5, 0xda, 0x75, 0x62, 0x19, 0x14, 0x6a, 0x26, 0x2d, 0xeb, 0xf8, 0xaf, 0x37, 0xf0,
0x6c, 0xa4, 0x55, 0xb1, 0xbc, 0xe2, 0x33, 0xc0, 0x9a, 0xca, 0xb0, 0x11, 0x49, 0x4f, 0x68,
0x9b, 0x3b, 0x6b, 0x3c, 0xcc, 0x13, 0xf6, 0xc7, 0x85, 0x61, 0x68, 0x42, 0xae, 0xbb, 0xdd,
0xcd, 0x45, 0x16, 0x29, 0x1d, 0xea, 0xdb, 0xc8, 0x03, 0x94, 0x3c, 0xee, 0x4f, 0x82, 0x11,
0xc3, 0xec, 0x28, 0xbd, 0x97, 0x05, 0x99, 0xde, 0xd7, 0xbb, 0x5e, 0x22, 0x1f, 0xd4, 0xeb,
0x64, 0xd9, 0x92, 0xd9, 0x85, 0xb7, 0x6a, 0x05, 0x6a, 0xe4, 0x24, 0x41, 0xf1, 0xcd, 0xf0,
0xd8, 0x3f, 0xf8, 0x9e, 0x0e, 0xcd, 0x0b, 0x7a, 0x70, 0x6b, 0x5a, 0x75, 0x0a, 0x6a, 0x33,
0x88, 0xec, 0x17, 0x75, 0x08, 0x70, 0x10, 0x2f, 0x24, 0xcf, 0xc4, 0xe9, 0x42, 0x00, 0x61,
0x94, 0xca, 0x1f, 0x3a, 0x76, 0x06, 0xfa, 0xd2, 0x48, 0x81, 0xf0, 0x77, 0x60, 0x03, 0x45,
0xd9, 0x61, 0xf4, 0xa4, 0x6f, 0x3d, 0xd9, 0x30, 0xc3, 0x04, 0x6b, 0x54, 0x2a, 0xb7, 0xec,
0x3b, 0xf4, 0x4b, 0xf5, 0x68, 0x52, 0x26, 0xce, 0xff, 0x5d, 0x19, 0x91, 0xa0, 0xa3, 0xa5,
0xa9, 0xb1, 0xe0, 0x23, 0xc4, 0x0a, 0x77, 0x4d, 0xf9, 0x51, 0x20, 0xa3, 0xa5, 0xa9, 0xb1,
0xc1, 0x00, 0x82, 0x86, 0x8e, 0x7f, 0x5d, 0x19, 0x91, 0xa0, 0xa3, 0xc4, 0xeb, 0x54, 0x0b,
0x75, 0x68, 0x52, 0x07, 0x8c, 0x9a, 0x97, 0x8d, 0x79, 0x70, 0x62, 0x46, 0xef, 0x5c, 0x1b,
0x95, 0x89, 0x71, 0x41, 0xe1, 0x21, 0xa1, 0xa1, 0xa1, 0xc0, 0x02, 0x67, 0x4c, 0x1a, 0xb6,
0xcf, 0xfd, 0x78, 0x53, 0x24, 0xab, 0xb5, 0xc9, 0xf1, 0x60, 0x23, 0xa5, 0xc8, 0x12, 0x87,
0x6d, 0x58, 0x13, 0x85, 0x88, 0x92, 0x87, 0x6d, 0x58, 0x32, 0xc7, 0x0c, 0x9a, 0x97, 0xac,
0xda, 0x36, 0xee, 0x5e, 0x3e, 0xdf, 0x1d, 0xb8, 0xf2, 0x66, 0x2f, 0xbd, 0xf8, 0x72, 0x47,
0xed, 0x58, 0x13, 0x85, 0x88, 0x92, 0x87, 0x8c, 0x7b, 0x55, 0x09, 0x90, 0xa2, 0xc6, 0xef,
0x3d, 0xf8, 0x53, 0x24, 0xab, 0xd4, 0x2a, 0xb7, 0xec, 0x5a, 0x36, 0xee, 0x5e, 0x3e, 0xdf,
0x3c, 0xfa, 0x76, 0x4f, 0xfd, 0x59, 0x30, 0xe2, 0x46, 0xef, 0x3d, 0xf8, 0x53, 0x05, 0x69,
0x31, 0xc1, 0x00, 0x82, 0x86, 0x8e, 0x7f, 0x5d, 0x19, 0xb0, 0xe2, 0x27, 0xcc, 0xfb, 0x74,
0x4b, 0x14, 0x8b, 0x94, 0x8b, 0x75, 0x68, 0x33, 0xc5, 0x08, 0x92, 0x87, 0x8c, 0x9a, 0xb6,
0xcf, 0x1c, 0xba, 0xd7, 0x0d, 0x98, 0xb2, 0xe6, 0x2f, 0xdc, 0x1b, 0x95, 0x89, 0x71, 0x60,
0x23, 0xc4, 0x0a, 0x96, 0x8f, 0x9c, 0xba, 0xf6, 0x6e, 0x3f, 0xfc, 0x5b, 0x15, 0xa8, 0xd2,
0x26, 0xaf, 0xbd, 0xf8, 0x72, 0x66, 0x2f, 0xdc, 0x1b, 0xb4, 0xcb, 0x14, 0x8b, 0x94, 0xaa,
0xb7, 0xcd, 0xf9, 0x51, 0x01, 0x80, 0x82, 0x86, 0x6f, 0x3d, 0xd9, 0x30, 0xe2, 0x27, 0xcc,
0xfb, 0x74, 0x4b, 0x14, 0xaa, 0xb7, 0xcd, 0xf9, 0x70, 0x43, 0x04, 0x6b, 0x35, 0xc9, 0xf1,
0x60, 0x23, 0xa5, 0xc8, 0xf3, 0x45, 0x08, 0x92, 0x87, 0x6d, 0x58, 0x32, 0xe6, 0x2f, 0xbd,
0xf8, 0x72, 0x66, 0x4e, 0x1e, 0xbe, 0xfe, 0x7e, 0x7e, 0x7e, 0x5f, 0x1d, 0x99, 0x91, 0xa0,
0xa3, 0xc4, 0x0a, 0x77, 0x4d, 0x18, 0x93, 0xa4, 0xab, 0xd4, 0x0b, 0x75, 0x49, 0x10, 0xa2,
0xc6, 0xef, 0x3d, 0xf8, 0x53, 0x24, 0xab, 0xb5, 0xe8, 0x33, 0xe4, 0x4a, 0x16, 0xae, 0xde,
0x1f, 0xbc, 0xdb, 0x15, 0xa8, 0xb3, 0xc5, 0x08, 0x73, 0x45, 0xe9, 0x31, 0xc1, 0xe1, 0x21,
0xa1, 0xa1, 0xa1, 0xc0, 0x02, 0x86, 0x6f, 0x5c, 0x3a, 0xd7, 0x0d, 0x98, 0x93, 0xa4, 0xca,
0x16, 0xae, 0xde, 0x1f, 0x9d, 0x99, 0xb0, 0xe2, 0x46, 0xef, 0x3d, 0xf8, 0x72, 0x47, 0x0c,
0x9a, 0xb6, 0xcf, 0xfd, 0x59, 0x11, 0xa0, 0xa3, 0xa5, 0xc8, 0xf3, 0x45, 0x08, 0x92, 0x87,
0x6d, 0x39, 0xf0, 0x43, 0x04, 0x8a, 0x96, 0xae, 0xde, 0x3e, 0xdf, 0x1d, 0x99, 0x91, 0xa0,
0xc2, 0x06, 0x6f, 0x3d, 0xf8, 0x72, 0x47, 0x0c, 0x9a, 0x97, 0x8d, 0x98, 0x93, 0x85, 0x88,
0x73, 0x45, 0xe9, 0x31, 0xe0, 0x23, 0xa5, 0xa9, 0xd0, 0x03, 0x84, 0x8a, 0x96, 0xae, 0xde,
0x1f, 0xbc, 0xdb, 0x15, 0xa8, 0xd2, 0x26, 0xce, 0xff, 0x5d, 0x19, 0x91, 0x81, 0x80, 0x82,
0x67, 0x2d, 0xd8, 0x13, 0xa4, 0xab, 0xd4, 0x0b, 0x94, 0xaa, 0xb7, 0xcd, 0xf9, 0x51, 0x20,
0xa3, 0xa5, 0xc8, 0xf3, 0x45, 0xe9, 0x50, 0x22, 0xc6, 0xef, 0x5c, 0x3a, 0xd7, 0x0d, 0x98,
0x93, 0x85, 0x88, 0x73, 0x64, 0x4a, 0xf7, 0x4d, 0xf9, 0x51, 0x20, 0xa3, 0xc4, 0x0a, 0x96,
0xae, 0xde, 0x3e, 0xfe, 0x7e, 0x7e, 0x7e, 0x5f, 0x3c, 0xfa, 0x76, 0x4f, 0xfd, 0x78, 0x72,
0x66, 0x2f, 0xbd, 0xd9, 0x30, 0xc3, 0xe5, 0x48, 0x12, 0x87, 0x8c, 0x7b, 0x55, 0x28, 0xd2,
0x07, 0x8c, 0x9a, 0x97, 0xac, 0xda, 0x17, 0x8d, 0x79, 0x51, 0x20, 0xa3, 0xc4, 0xeb, 0x54,
0x0b, 0x94, 0x8b, 0x94, 0xaa, 0xd6, 0x2e, 0xbf, 0xfc, 0x5b, 0x15, 0xa8, 0xd2, 0x26, 0xaf,
0xdc, 0x1b, 0xb4, 0xea, 0x37, 0xec, 0x3b, 0xf4, 0x6a, 0x37, 0xcd, 0x18, 0x93, 0x85, 0x69,
0x31, 0xc1, 0xe1, 0x40, 0xe3, 0x25, 0xc8, 0x12, 0x87, 0x8c, 0x9a, 0xb6, 0xcf, 0xfd, 0x59,
0x11, 0xa0, 0xc2, 0x06, 0x8e, 0x7f, 0x5d, 0x38, 0xf2, 0x47, 0x0c, 0x7b, 0x74, 0x6a, 0x37,
0xec, 0x5a, 0x36, 0xee, 0x3f, 0xfc, 0x7a, 0x76, 0x4f, 0x1c, 0x9b, 0x95, 0x89, 0x71, 0x41,
0x00, 0x63, 0x44, 0xeb, 0x54, 0x2a, 0xd6, 0x0f, 0x9c, 0xba, 0xd7, 0x0d, 0x98, 0x93, 0x85,
0x69, 0x31, 0xc1, 0x00, 0x82, 0x86, 0x8e, 0x9e, 0xbe, 0xdf, 0x3c, 0xfa, 0x57, 0x2c, 0xda,
0x36, 0xee, 0x3f, 0xfc, 0x5b, 0x15, 0x89, 0x71, 0x41, 0x00, 0x82, 0x86, 0x8e, 0x7f, 0x5d,
0x38, 0xf2, 0x47, 0xed, 0x58, 0x13, 0xa4, 0xca, 0xf7, 0x4d, 0xf9, 0x51, 0x01, 0x80, 0x63,
0x44, 0xeb, 0x54, 0x2a, 0xd6, 0x2e, 0xbf, 0xdd, 0x19, 0x91, 0xa0, 0xa3, 0xa5, 0xa9, 0xb1,
0xe0, 0x42, 0x06, 0x8e, 0x7f, 0x5d, 0x19, 0x91, 0xa0, 0xa3, 0xc4, 0x0a, 0x96, 0x8f, 0x7d,
0x78, 0x72, 0x47, 0x0c, 0x7b, 0x74, 0x6a, 0x56, 0x2e, 0xde, 0x1f, 0xbc, 0xfa, 0x57, 0x0d,
0x79, 0x51, 0x01, 0x61, 0x21, 0xa1, 0xc0, 0xe3, 0x25, 0xa9, 0xb1, 0xc1, 0xe1, 0x40, 0x02,
0x67, 0x4c, 0x1a, 0x97, 0x8d, 0x98, 0x93, 0xa4, 0xab, 0xd4, 0x2a, 0xd6, 0x0f, 0x9c, 0x9b,
0xb4, 0xcb, 0x14, 0xaa, 0xb7, 0xcd, 0xf9, 0x51, 0x20, 0xa3, 0xc4, 0xeb, 0x35, 0xc9, 0xf1,
0x60, 0x42, 0x06, 0x8e, 0x7f, 0x7c, 0x7a, 0x76, 0x6e, 0x3f, 0xfc, 0x7a, 0x76, 0x6e, 0x5e,
0x3e, 0xfe, 0x7e, 0x5f, 0x3c, 0xdb, 0x15, 0x89, 0x71, 0x41, 0xe1, 0x21, 0xc0, 0xe3, 0x44,
0xeb, 0x54, 0x2a, 0xb7, 0xcd, 0xf9, 0x70, 0x62, 0x27, 0xad, 0xd8, 0x32, 0xc7, 0x0c, 0x7b,
0x74, 0x4b, 0x14, 0xaa, 0xb7, 0xec, 0x3b, 0xd5, 0x28, 0xd2, 0x07, 0x6d, 0x39, 0xd1, 0x20,
0xc2, 0xe7, 0x4c, 0x1a, 0x97, 0x8d, 0x98, 0xb2, 0xc7, 0x0c, 0x59, 0x28, 0xf3, 0x9b };

/* USER CODE END PV */

void SystemClock_Config(void);
static void MX_GPIO_Init(void);
static void MX_DMA_Init(void);
static void MX_USART3_UART_Init(void);
static void MX_USB_OTG_FS_PCD_Init(void);
static void MX_SPI4_Init(void);
static void MX_UART7_Init(void);
static void MX_USART2_UART_Init(void);
static void MX_I2C1_Init(void);
void StartControlTask(void *argument);
void StartCommBoard(void *argument);
void StartSensorRead(void *argument);
void StartSafety(void *argument);

/* USER CODE BEGIN 0 */

// Struct to store sensor values
struct sensValue{

	bool mouseMotion;

    int16_t mouse_D_X;
    int16_t mouse_D_Y;

}typedef sensValue;

struct structMessageStructHeaderFromNano {

	unsigned char frameType;
	unsigned char frameLength;

}typedef messageStructHeaderFromNano;

struct structMouseSensorMessage {

	short XMagnitud;
	short YMagnitud;

}typedef mouseSensorMessage;

struct structMessageStructFromNucelo {

    unsigned char statusOfNucelo;
    short motorStatus[NUMBER_OF_MOTORS];

    unsigned char proximitySensor[NUMBER_OF_PROXIMITY_SENSORS];
    mouseSensorMessage mouseSensor[NUMBER_OF_MOUSE_SESNORS];

}typedef messageStructFromNucleo;

// Read memory registers from SPI on channel E
void SPI_E_ReadReg(uint8_t *REG_ADDR, uint8_t *readByte );

// Write memory registers from SPI on channel E
void SPI_E_WriteReg(uint8_t *REG_ADDR, uint8_t *readByte );

// Plot sensor data to a computer terminal via USB cable
void plotSensorData(sensValue *dataToPlot);

// Setup for the mouse sensor.
void startUpMouse();

// Read mouse sensor
void readMouseSensor(sensValue *sensorPacket);

// Handle received I2C messages.
void I2CCommandHandle();

/* USER CODE END 0 */

int main(void)
{

  /* MCU Configuration--------------------------------------------------------*/

  /* Reset of all peripherals, Initializes the Flash interface and the Systick. */
  HAL_Init();

  /* Configure the system clock */
  SystemClock_Config();

  /* USER CODE BEGIN SysInit */

  HAL_I2C_MspInit(&hi2c1);

  /* USER CODE END SysInit */

  /* Initialize all configured peripherals */
  MX_GPIO_Init();
  MX_DMA_Init();
  MX_USART3_UART_Init();
  MX_USB_OTG_FS_PCD_Init();
  MX_SPI4_Init();
  MX_UART7_Init();
  MX_USART2_UART_Init();
  MX_I2C1_Init();
  /* USER CODE BEGIN 2 */

  HAL_GPIO_WritePin(GPIOE,GPIO_PIN_4,GPIO_PIN_SET);

  /* USER CODE END 2 */

  /* Init scheduler */
  osKernelInitialize();

  /* Create the thread(s) */
  /* creation of ControlTask */
  ControlTaskHandle = osThreadNew(StartControlTask, NULL, &ControlTask_attributes);

  /* creation of CommBoard */
  CommBoardHandle = osThreadNew(StartCommBoard, NULL, &CommBoard_attributes);

  /* creation of SensorRead */
  SensorReadHandle = osThreadNew(StartSensorRead, NULL, &SensorRead_attributes);

  /* creation of Safety */
  SafetyHandle = osThreadNew(StartSafety, NULL, &Safety_attributes);

  /* Start scheduler */
  osKernelStart();

  /* We should never get here as control is now taken by the scheduler */
  /* Infinite loop */
  while (1)
  {

  }
}

void SystemClock_Config(void)
{
  RCC_OscInitTypeDef RCC_OscInitStruct = {0};
  RCC_ClkInitTypeDef RCC_ClkInitStruct = {0};
  RCC_PeriphCLKInitTypeDef PeriphClkInitStruct = {0};

  /** Supply configuration update enable
  */
  HAL_PWREx_ConfigSupply(PWR_LDO_SUPPLY);
  /** Configure the main internal regulator output voltage
  */
  __HAL_PWR_VOLTAGESCALING_CONFIG(PWR_REGULATOR_VOLTAGE_SCALE3);

  while(!__HAL_PWR_GET_FLAG(PWR_FLAG_VOSRDY)) {}
  /** Initializes the RCC Oscillators according to the specified parameters
  * in the RCC_OscInitTypeDef structure.
  */
  RCC_OscInitStruct.OscillatorType = RCC_OSCILLATORTYPE_HSI|RCC_OSCILLATORTYPE_HSE;
  RCC_OscInitStruct.HSEState = RCC_HSE_BYPASS;
  RCC_OscInitStruct.HSIState = RCC_HSI_DIV1;
  RCC_OscInitStruct.HSICalibrationValue = RCC_HSICALIBRATION_DEFAULT;
  RCC_OscInitStruct.PLL.PLLState = RCC_PLL_ON;
  RCC_OscInitStruct.PLL.PLLSource = RCC_PLLSOURCE_HSE;
  RCC_OscInitStruct.PLL.PLLM = 1;
  RCC_OscInitStruct.PLL.PLLN = 24;
  RCC_OscInitStruct.PLL.PLLP = 2;
  RCC_OscInitStruct.PLL.PLLQ = 4;
  RCC_OscInitStruct.PLL.PLLR = 2;
  RCC_OscInitStruct.PLL.PLLRGE = RCC_PLL1VCIRANGE_3;
  RCC_OscInitStruct.PLL.PLLVCOSEL = RCC_PLL1VCOWIDE;
  RCC_OscInitStruct.PLL.PLLFRACN = 0;
  if (HAL_RCC_OscConfig(&RCC_OscInitStruct) != HAL_OK)
  {
    Error_Handler();
  }
  /** Initializes the CPU, AHB and APB buses clocks
  */
  RCC_ClkInitStruct.ClockType = RCC_CLOCKTYPE_HCLK|RCC_CLOCKTYPE_SYSCLK
                              |RCC_CLOCKTYPE_PCLK1|RCC_CLOCKTYPE_PCLK2
                              |RCC_CLOCKTYPE_D3PCLK1|RCC_CLOCKTYPE_D1PCLK1;
  RCC_ClkInitStruct.SYSCLKSource = RCC_SYSCLKSOURCE_HSI;
  RCC_ClkInitStruct.SYSCLKDivider = RCC_SYSCLK_DIV1;
  RCC_ClkInitStruct.AHBCLKDivider = RCC_HCLK_DIV1;
  RCC_ClkInitStruct.APB3CLKDivider = RCC_APB3_DIV1;
  RCC_ClkInitStruct.APB1CLKDivider = RCC_APB1_DIV1;
  RCC_ClkInitStruct.APB2CLKDivider = RCC_APB2_DIV1;
  RCC_ClkInitStruct.APB4CLKDivider = RCC_APB4_DIV1;

  if (HAL_RCC_ClockConfig(&RCC_ClkInitStruct, FLASH_LATENCY_0) != HAL_OK)
  {
    Error_Handler();
  }
  PeriphClkInitStruct.PeriphClockSelection = RCC_PERIPHCLK_USART3|RCC_PERIPHCLK_USART2
                              |RCC_PERIPHCLK_UART7|RCC_PERIPHCLK_SPI4
                              |RCC_PERIPHCLK_I2C1|RCC_PERIPHCLK_USB;
  PeriphClkInitStruct.Spi45ClockSelection = RCC_SPI45CLKSOURCE_D2PCLK1;
  PeriphClkInitStruct.Usart234578ClockSelection = RCC_USART234578CLKSOURCE_D2PCLK1;
  PeriphClkInitStruct.I2c123ClockSelection = RCC_I2C123CLKSOURCE_D2PCLK1;
  PeriphClkInitStruct.UsbClockSelection = RCC_USBCLKSOURCE_PLL;
  if (HAL_RCCEx_PeriphCLKConfig(&PeriphClkInitStruct) != HAL_OK)
  {
    Error_Handler();
  }
  /** Enable USB Voltage detector
  */
  HAL_PWREx_EnableUSBVoltageDetector();
}

static void MX_I2C1_Init(void)
{

  hi2c1.Instance = I2C1;
  hi2c1.Init.Timing = 0x00602173;
  hi2c1.Init.OwnAddress1 = 10;
  hi2c1.Init.AddressingMode = I2C_ADDRESSINGMODE_7BIT;
  hi2c1.Init.DualAddressMode = I2C_DUALADDRESS_DISABLE;
  hi2c1.Init.OwnAddress2 = 0;
  hi2c1.Init.OwnAddress2Masks = I2C_OA2_NOMASK;
  hi2c1.Init.GeneralCallMode = I2C_GENERALCALL_DISABLE;
  hi2c1.Init.NoStretchMode = I2C_NOSTRETCH_DISABLE;
  if (HAL_I2C_Init(&hi2c1) != HAL_OK)
  {
    Error_Handler();
  }
  /** Configure Analogue filter
  */
  if (HAL_I2CEx_ConfigAnalogFilter(&hi2c1, I2C_ANALOGFILTER_ENABLE) != HAL_OK)
  {
    Error_Handler();
  }
  /** Configure Digital filter
  */
  if (HAL_I2CEx_ConfigDigitalFilter(&hi2c1, 0) != HAL_OK)
  {
    Error_Handler();
  }

}

static void MX_SPI4_Init(void)
{

  /* SPI4 parameter configuration*/
  hspi4.Instance = SPI4;
  hspi4.Init.Mode = SPI_MODE_MASTER;
  hspi4.Init.Direction = SPI_DIRECTION_2LINES;
  hspi4.Init.DataSize = SPI_DATASIZE_8BIT;
  hspi4.Init.CLKPolarity = SPI_POLARITY_HIGH;
  hspi4.Init.CLKPhase = SPI_PHASE_2EDGE;
  hspi4.Init.NSS = SPI_NSS_SOFT;
  hspi4.Init.BaudRatePrescaler = SPI_BAUDRATEPRESCALER_256;
  hspi4.Init.FirstBit = SPI_FIRSTBIT_MSB;
  hspi4.Init.TIMode = SPI_TIMODE_DISABLE;
  hspi4.Init.CRCCalculation = SPI_CRCCALCULATION_DISABLE;
  hspi4.Init.CRCPolynomial = 0x0;
  hspi4.Init.NSSPMode = SPI_NSS_PULSE_DISABLE;
  hspi4.Init.NSSPolarity = SPI_NSS_POLARITY_LOW;
  hspi4.Init.FifoThreshold = SPI_FIFO_THRESHOLD_01DATA;
  hspi4.Init.TxCRCInitializationPattern = SPI_CRC_INITIALIZATION_ALL_ZERO_PATTERN;
  hspi4.Init.RxCRCInitializationPattern = SPI_CRC_INITIALIZATION_ALL_ZERO_PATTERN;
  hspi4.Init.MasterSSIdleness = SPI_MASTER_SS_IDLENESS_00CYCLE;
  hspi4.Init.MasterInterDataIdleness = SPI_MASTER_INTERDATA_IDLENESS_00CYCLE;
  hspi4.Init.MasterReceiverAutoSusp = SPI_MASTER_RX_AUTOSUSP_DISABLE;
  hspi4.Init.MasterKeepIOState = SPI_MASTER_KEEP_IO_STATE_DISABLE;
  hspi4.Init.IOSwap = SPI_IO_SWAP_DISABLE;
  if (HAL_SPI_Init(&hspi4) != HAL_OK)
  {
    Error_Handler();
  }

}

static void MX_UART7_Init(void)
{

  huart7.Instance = UART7;
  huart7.Init.BaudRate = 1000000;
  huart7.Init.WordLength = UART_WORDLENGTH_8B;
  huart7.Init.StopBits = UART_STOPBITS_1;
  huart7.Init.Parity = UART_PARITY_NONE;
  huart7.Init.Mode = UART_MODE_TX_RX;
  huart7.Init.HwFlowCtl = UART_HWCONTROL_NONE;
  huart7.Init.OverSampling = UART_OVERSAMPLING_16;
  huart7.Init.OneBitSampling = UART_ONE_BIT_SAMPLE_DISABLE;
  huart7.Init.ClockPrescaler = UART_PRESCALER_DIV1;
  huart7.AdvancedInit.AdvFeatureInit = UART_ADVFEATURE_NO_INIT;
  if (HAL_HalfDuplex_Init(&huart7) != HAL_OK)
  {
    Error_Handler();
  }
  if (HAL_UARTEx_SetTxFifoThreshold(&huart7, UART_TXFIFO_THRESHOLD_1_8) != HAL_OK)
  {
    Error_Handler();
  }
  if (HAL_UARTEx_SetRxFifoThreshold(&huart7, UART_RXFIFO_THRESHOLD_1_8) != HAL_OK)
  {
    Error_Handler();
  }
  if (HAL_UARTEx_DisableFifoMode(&huart7) != HAL_OK)
  {
    Error_Handler();
  }

}

static void MX_USART2_UART_Init(void)
{

  huart2.Instance = USART2;
  huart2.Init.BaudRate = 1000000;
  huart2.Init.WordLength = UART_WORDLENGTH_8B;
  huart2.Init.StopBits = UART_STOPBITS_1;
  huart2.Init.Parity = UART_PARITY_NONE;
  huart2.Init.Mode = UART_MODE_TX_RX;
  huart2.Init.HwFlowCtl = UART_HWCONTROL_NONE;
  huart2.Init.OverSampling = UART_OVERSAMPLING_16;
  huart2.Init.OneBitSampling = UART_ONE_BIT_SAMPLE_DISABLE;
  huart2.Init.ClockPrescaler = UART_PRESCALER_DIV1;
  huart2.AdvancedInit.AdvFeatureInit = UART_ADVFEATURE_NO_INIT;
  if (HAL_HalfDuplex_Init(&huart2) != HAL_OK)
  {
    Error_Handler();
  }
  if (HAL_UARTEx_SetTxFifoThreshold(&huart2, UART_TXFIFO_THRESHOLD_1_8) != HAL_OK)
  {
    Error_Handler();
  }
  if (HAL_UARTEx_SetRxFifoThreshold(&huart2, UART_RXFIFO_THRESHOLD_1_8) != HAL_OK)
  {
    Error_Handler();
  }
  if (HAL_UARTEx_DisableFifoMode(&huart2) != HAL_OK)
  {
    Error_Handler();
  }

}

static void MX_USART3_UART_Init(void)
{

  huart3.Instance = USART3;
  huart3.Init.BaudRate = 115200;
  huart3.Init.WordLength = UART_WORDLENGTH_8B;
  huart3.Init.StopBits = UART_STOPBITS_1;
  huart3.Init.Parity = UART_PARITY_NONE;
  huart3.Init.Mode = UART_MODE_TX_RX;
  huart3.Init.HwFlowCtl = UART_HWCONTROL_NONE;
  huart3.Init.OverSampling = UART_OVERSAMPLING_16;
  huart3.Init.OneBitSampling = UART_ONE_BIT_SAMPLE_DISABLE;
  huart3.Init.ClockPrescaler = UART_PRESCALER_DIV1;
  huart3.AdvancedInit.AdvFeatureInit = UART_ADVFEATURE_NO_INIT;
  if (HAL_UART_Init(&huart3) != HAL_OK)
  {
    Error_Handler();
  }
  if (HAL_UARTEx_SetTxFifoThreshold(&huart3, UART_TXFIFO_THRESHOLD_1_8) != HAL_OK)
  {
    Error_Handler();
  }
  if (HAL_UARTEx_SetRxFifoThreshold(&huart3, UART_RXFIFO_THRESHOLD_1_8) != HAL_OK)
  {
    Error_Handler();
  }
  if (HAL_UARTEx_DisableFifoMode(&huart3) != HAL_OK)
  {
    Error_Handler();
  }

}

static void MX_USB_OTG_FS_PCD_Init(void)
{

  hpcd_USB_OTG_FS.Instance = USB_OTG_FS;
  hpcd_USB_OTG_FS.Init.dev_endpoints = 9;
  hpcd_USB_OTG_FS.Init.speed = PCD_SPEED_FULL;
  hpcd_USB_OTG_FS.Init.dma_enable = DISABLE;
  hpcd_USB_OTG_FS.Init.phy_itface = PCD_PHY_EMBEDDED;
  hpcd_USB_OTG_FS.Init.Sof_enable = ENABLE;
  hpcd_USB_OTG_FS.Init.low_power_enable = DISABLE;
  hpcd_USB_OTG_FS.Init.lpm_enable = DISABLE;
  hpcd_USB_OTG_FS.Init.battery_charging_enable = ENABLE;
  hpcd_USB_OTG_FS.Init.vbus_sensing_enable = ENABLE;
  hpcd_USB_OTG_FS.Init.use_dedicated_ep1 = DISABLE;
  if (HAL_PCD_Init(&hpcd_USB_OTG_FS) != HAL_OK)
  {
    Error_Handler();
  }

}

static void MX_DMA_Init(void)
{

  /* DMA controller clock enable */
  __HAL_RCC_DMA1_CLK_ENABLE();

  /* DMA interrupt init */
  /* DMA1_Stream0_IRQn interrupt configuration */
  HAL_NVIC_SetPriority(DMA1_Stream0_IRQn, 0, 0);
  HAL_NVIC_EnableIRQ(DMA1_Stream0_IRQn);

}

static void MX_GPIO_Init(void)
{
  GPIO_InitTypeDef GPIO_InitStruct = {0};

  /* GPIO Ports Clock Enable */
  __HAL_RCC_GPIOE_CLK_ENABLE();
  __HAL_RCC_GPIOC_CLK_ENABLE();
  __HAL_RCC_GPIOF_CLK_ENABLE();
  __HAL_RCC_GPIOH_CLK_ENABLE();
  __HAL_RCC_GPIOA_CLK_ENABLE();
  __HAL_RCC_GPIOB_CLK_ENABLE();
  __HAL_RCC_GPIOD_CLK_ENABLE();
  __HAL_RCC_GPIOG_CLK_ENABLE();

  /*Configure GPIO pin Output Level */
  HAL_GPIO_WritePin(GPIOE, GPIO_PIN_4|LD2_Pin, GPIO_PIN_RESET);

  /*Configure GPIO pin Output Level */
  HAL_GPIO_WritePin(GPIOA, GPIO_PIN_1, GPIO_PIN_RESET);

  /*Configure GPIO pin Output Level */
  HAL_GPIO_WritePin(GPIOB, GPIO_PIN_0|LD3_Pin, GPIO_PIN_RESET);

  /*Configure GPIO pin Output Level */
  HAL_GPIO_WritePin(USB_OTG_FS_PWR_EN_GPIO_Port, USB_OTG_FS_PWR_EN_Pin, GPIO_PIN_RESET);

  /*Configure GPIO pins : PE4 LD2_Pin */
  GPIO_InitStruct.Pin = GPIO_PIN_4|LD2_Pin;
  GPIO_InitStruct.Mode = GPIO_MODE_OUTPUT_PP;
  GPIO_InitStruct.Pull = GPIO_NOPULL;
  GPIO_InitStruct.Speed = GPIO_SPEED_FREQ_LOW;
  HAL_GPIO_Init(GPIOE, &GPIO_InitStruct);

  /*Configure GPIO pin : B1_Pin */
  GPIO_InitStruct.Pin = B1_Pin;
  GPIO_InitStruct.Mode = GPIO_MODE_INPUT;
  GPIO_InitStruct.Pull = GPIO_NOPULL;
  HAL_GPIO_Init(B1_GPIO_Port, &GPIO_InitStruct);

  /*Configure GPIO pins : PC1 PC4 PC5 */
  GPIO_InitStruct.Pin = GPIO_PIN_1|GPIO_PIN_4|GPIO_PIN_5;
  GPIO_InitStruct.Mode = GPIO_MODE_AF_PP;
  GPIO_InitStruct.Pull = GPIO_NOPULL;
  GPIO_InitStruct.Speed = GPIO_SPEED_FREQ_LOW;
  GPIO_InitStruct.Alternate = GPIO_AF11_ETH;
  HAL_GPIO_Init(GPIOC, &GPIO_InitStruct);

  /*Configure GPIO pin : PA1 */
  GPIO_InitStruct.Pin = GPIO_PIN_1;
  GPIO_InitStruct.Mode = GPIO_MODE_OUTPUT_PP;
  GPIO_InitStruct.Pull = GPIO_NOPULL;
  GPIO_InitStruct.Speed = GPIO_SPEED_FREQ_LOW;
  HAL_GPIO_Init(GPIOA, &GPIO_InitStruct);

  /*Configure GPIO pin : PA7 */
  GPIO_InitStruct.Pin = GPIO_PIN_7;
  GPIO_InitStruct.Mode = GPIO_MODE_AF_PP;
  GPIO_InitStruct.Pull = GPIO_NOPULL;
  GPIO_InitStruct.Speed = GPIO_SPEED_FREQ_LOW;
  GPIO_InitStruct.Alternate = GPIO_AF11_ETH;
  HAL_GPIO_Init(GPIOA, &GPIO_InitStruct);

  /*Configure GPIO pins : PB0 LD3_Pin */
  GPIO_InitStruct.Pin = GPIO_PIN_0|LD3_Pin;
  GPIO_InitStruct.Mode = GPIO_MODE_OUTPUT_PP;
  GPIO_InitStruct.Pull = GPIO_NOPULL;
  GPIO_InitStruct.Speed = GPIO_SPEED_FREQ_LOW;
  HAL_GPIO_Init(GPIOB, &GPIO_InitStruct);

  /*Configure GPIO pin : PB13 */
  GPIO_InitStruct.Pin = GPIO_PIN_13;
  GPIO_InitStruct.Mode = GPIO_MODE_AF_PP;
  GPIO_InitStruct.Pull = GPIO_NOPULL;
  GPIO_InitStruct.Speed = GPIO_SPEED_FREQ_LOW;
  GPIO_InitStruct.Alternate = GPIO_AF11_ETH;
  HAL_GPIO_Init(GPIOB, &GPIO_InitStruct);

  /*Configure GPIO pin : USB_OTG_FS_PWR_EN_Pin */
  GPIO_InitStruct.Pin = USB_OTG_FS_PWR_EN_Pin;
  GPIO_InitStruct.Mode = GPIO_MODE_OUTPUT_PP;
  GPIO_InitStruct.Pull = GPIO_NOPULL;
  GPIO_InitStruct.Speed = GPIO_SPEED_FREQ_LOW;
  HAL_GPIO_Init(USB_OTG_FS_PWR_EN_GPIO_Port, &GPIO_InitStruct);

  /*Configure GPIO pin : USB_OTG_FS_OVCR_Pin */
  GPIO_InitStruct.Pin = USB_OTG_FS_OVCR_Pin;
  GPIO_InitStruct.Mode = GPIO_MODE_IT_RISING;
  GPIO_InitStruct.Pull = GPIO_NOPULL;
  HAL_GPIO_Init(USB_OTG_FS_OVCR_GPIO_Port, &GPIO_InitStruct);

  /*Configure GPIO pins : PG11 PG13 */
  GPIO_InitStruct.Pin = GPIO_PIN_11|GPIO_PIN_13;
  GPIO_InitStruct.Mode = GPIO_MODE_AF_PP;
  GPIO_InitStruct.Pull = GPIO_NOPULL;
  GPIO_InitStruct.Speed = GPIO_SPEED_FREQ_LOW;
  GPIO_InitStruct.Alternate = GPIO_AF11_ETH;
  HAL_GPIO_Init(GPIOG, &GPIO_InitStruct);

}

/* USER CODE BEGIN 4 */

void SPI_E_ReadReg(uint8_t *REG_ADDR, uint8_t *readByte )
{
  char READ_REG_ADDR;
  READ_REG_ADDR = *REG_ADDR & 0x7F;

  HAL_GPIO_WritePin( GPIOE,GPIO_PIN_4,GPIO_PIN_RESET);

  HAL_SPI_Transmit(&hspi4,(uint8_t *) &READ_REG_ADDR, 1, 100);

  HAL_SPI_Receive(&hspi4,(uint8_t *) readByte, 1, 100);

  //HAL_Delay(5);
  osDelay(1);

  HAL_GPIO_WritePin(GPIOE,GPIO_PIN_4,GPIO_PIN_SET);

  osDelay(1);

}

void SPI_E_WriteReg(uint8_t *REG_ADDR, uint8_t *sendByte )
{
  char READ_REG_ADDR;
  READ_REG_ADDR = *REG_ADDR | 0x80;

  HAL_GPIO_WritePin( GPIOE,GPIO_PIN_4,GPIO_PIN_RESET);

  HAL_SPI_Transmit(&hspi4,(uint8_t *) &READ_REG_ADDR, 1, 100);

  HAL_SPI_Transmit(&hspi4,(uint8_t *) sendByte, 1, 100);

  //HAL_Delay(5);
  osDelay(1);

  HAL_GPIO_WritePin(GPIOE,GPIO_PIN_4,GPIO_PIN_SET);

  osDelay(1);

}

void startUpMouse()
{

  // Memory registers to read and write.
  uint8_t startUpRegAddr[] = {0x3A,0x02,0x03,0x04,0x05,0x06,0x10,0x13,0x13,0x62,0x2A,0x10};
  uint8_t sendByte;
  uint8_t readByte;

  // Ensure reset
  HAL_GPIO_WritePin( GPIOE,GPIO_PIN_4,GPIO_PIN_SET);
  osDelay(1);
  HAL_GPIO_WritePin( GPIOE,GPIO_PIN_4,GPIO_PIN_SET);
  osDelay(1);
  HAL_GPIO_WritePin( GPIOE,GPIO_PIN_4,GPIO_PIN_SET);
  osDelay(1);

  // Start up register
  sendByte = 0x5A;
  SPI_E_WriteReg(&startUpRegAddr[0], &sendByte );

  // Must wait 50 milliseconds.
  osDelay(50);
  // Read and discard data.
  SPI_E_ReadReg(&startUpRegAddr[1], &readByte );
  SPI_E_ReadReg(&startUpRegAddr[2], &readByte );
  SPI_E_ReadReg(&startUpRegAddr[3], &readByte );
  SPI_E_ReadReg(&startUpRegAddr[4], &readByte );
  SPI_E_ReadReg(&startUpRegAddr[5], &readByte );

  // Upload SROM data to mouse sensor.

  // Write 0 to Rest_En bit of Config2 register to disable Rest mode.
  sendByte = 0x00;
  SPI_E_WriteReg(&startUpRegAddr[6], &sendByte );

  // Write 0x1d to SROM_Enable register for initializing.
  sendByte = 0x1D;
  SPI_E_WriteReg(&startUpRegAddr[7], &sendByte );

  // Wait 10 ms
  osDelay(10);

  // Write 0x18 to SROM_Enable register again to start SROM download.
  sendByte = 0x18;
  SPI_E_WriteReg(&startUpRegAddr[8], &sendByte );

  // Send the SROM data
  // Select Slave during the whole transfer.
  HAL_GPIO_WritePin( GPIOE,GPIO_PIN_4,GPIO_PIN_RESET);
  // Select SROM_Load_Burst register
  HAL_SPI_Transmit(&hspi4, &startUpRegAddr[9], 1, 100);

  for(int i=0;i<firmware_length;i++)
  {
	  HAL_SPI_Transmit(&hspi4,(uint8_t *) &firmware_data[i], 1, 100);
	  osDelay(1);
  }

  HAL_GPIO_WritePin( GPIOE,GPIO_PIN_4,GPIO_PIN_SET);

  osDelay(1);

  // Read the SROM_ID (0x2A) register to verify the ID before any other register reads or writes.
  SPI_E_ReadReg(&startUpRegAddr[10], &readByte );

  // Write 0x00 to config2 register for wired mouse design.
  sendByte = 0x00;
  SPI_E_WriteReg(&startUpRegAddr[11], &sendByte );

  // Set Config1
  sendByte = 0x77;
  uint8_t conf1Addr = 0x0F;
  SPI_E_WriteReg(&conf1Addr, &sendByte );

}

void readMouseSensor(sensValue *sensorPacket)
{

	uint8_t readByte = 0;
	uint8_t freeze = 0x01;

	uint8_t motionADR[] = {0x02,0x03,0x04,0x05,0x06};
	uint8_t magnX_L = 0;
	uint8_t magnY_L = 0;
	// Write the motion address to freeze the current value of delta X and Y.
	SPI_E_WriteReg(&motionADR[0], &freeze );
	// Check if any motion has occurred.
	SPI_E_ReadReg(&motionADR[0], &readByte );
	// Save the motion bit.
	sensorPacket->mouseMotion = 0 < (0x80 & readByte);

	//Read the delta X registers.
	SPI_E_ReadReg(&motionADR[1], &readByte );
	magnX_L = (uint8_t) readByte;
	SPI_E_ReadReg(&motionADR[2], &readByte );

	// Merge the lower and higher bit values of the delta X registers.
	sensorPacket->mouse_D_X = magnX_L | (readByte<<8);

	//Read the delta X registers.
	SPI_E_ReadReg(&motionADR[3], &readByte );
	magnY_L = (uint8_t) readByte;
	SPI_E_ReadReg(&motionADR[4], &readByte );

	// Merge the lower and higher bit values of the delta Y registers.
	sensorPacket->mouse_D_Y = magnY_L | (readByte<<8);

}

void plotSensorData(sensValue *dataToPlot)
{

	// ASCII commands
	char CR = '\r';
	char NL = '\n';
	char TB = '\t';
	char MoveBack[] = "\033[F";

	//Text to send
	char mouseInfo[] = "Mouse Sensor:\n\r";
	char M_D_X[] = "Delta_X ";
	char M_D_Y[] = "Delta_Y ";

	char M_M[] = "Moving";
	char M_S[] = "Still ";

	int arrSize = 8;
	char u16charArr[arrSize];

	memset(u16charArr,'\0',arrSize);

	// Send mouse sensor data
	HAL_UART_Transmit(&huart3,(uint8_t *) mouseInfo, sizeof(mouseInfo), 100);

    // Convert sensor value
	//u16ToString( dataToPlot->mouse_D_X, u16charArr,5);

	sprintf(u16charArr, "%d", dataToPlot->mouse_D_X);

	// Send delta X
	HAL_UART_Transmit(&huart3,(uint8_t *) M_D_X, sizeof(M_D_X), 100);
    HAL_UART_Transmit(&huart3,(uint8_t *) u16charArr, arrSize, 100);

    // Convert sensor value
    //u16ToString( dataToPlot->mouse_D_Y, u16charArr,5);
    sprintf(u16charArr, "%d", dataToPlot->mouse_D_Y);
    // Send delta Y
    HAL_UART_Transmit(&huart3,(uint8_t *) M_D_Y, sizeof(M_D_Y), 100);
    HAL_UART_Transmit(&huart3,(uint8_t *) u16charArr, arrSize, 100);

    if(dataToPlot->mouseMotion)
      HAL_UART_Transmit(&huart3,(uint8_t *) M_M, sizeof(M_M), 100);
    else
	  HAL_UART_Transmit(&huart3,(uint8_t *) M_S, sizeof(M_S), 100);

    HAL_UART_Transmit(&huart3,(uint8_t *) &CR, 1, 100);
    HAL_UART_Transmit(&huart3,(uint8_t *) MoveBack, sizeof(MoveBack), 100);
    //HAL_UART_Transmit(&huart3,(uint8_t *) MoveBack, sizeof(MoveBack), 100);

}

void I2CCommandHandle( )
{
	/*
	 * Handles all received I2C messages. It reads the first 2 bytes as a frame.
	 * Then depending on the frame type it handle the command requested from the master.
	 */

	// Debug messages.
	const char strF[] = "I2C buffer is empty.\n\r";
	const char str0[] = "Undefined command.\n\r";
	const char str1[] = "Start the gripper.\n\r";
	const char str2[] = "Stop the gripper.\n\r";
	const char str3[] = "Release object.\n\r";
	const char str4[] = "Pause the gripper.\n\r";
	const char str5[] = "Set motor angle.\n\r";

	int arrSize = 30;
	char nrBuff[arrSize];

	// Standard receive packages.
	messageStructHeaderFromNano messageHeaderFromNano;

	// Indicate status of I2C.
	int I2CReceiveStatus;

	// Check if new I2C messages is available.
	I2CReceiveStatus = HAL_I2C_Slave_Receive(&hi2c1, (uint8_t *) &messageHeaderFromNano, (uint16_t) sizeof(messageStructHeaderFromNano), (uint32_t) 1);

	// Struggled to enable DMA.
	//I2CReceiveStatus = HAL_I2C_Slave_Receive_DMA(&hi2c1, (uint8_t *) &messageHeaderFromNano, (uint16_t) sizeof(messageStructHeaderFromNano));
//	sprintf(nrBuff, "Status Receive: %d \n\r", I2CReceiveStatus);
//	HAL_UART_Transmit(&huart3,(uint8_t *) nrBuff, arrSize, 100);

	// If there is a message, follow the instructions dependent of the type of message.
	if( I2CReceiveStatus == 0 )
	{

		// This switch case take care of each request from the master.
		switch(messageHeaderFromNano.frameType)
		{

			case 1:
			{
				// Should start the gripper
				HAL_UART_Transmit(&huart3,(uint8_t *) str1, sizeof(str1), 50);
			}
				break;

			case 2:
			{
				// Should stop the gripper and set it to the standby mode.
				HAL_UART_Transmit(&huart3,(uint8_t *) str2, sizeof(str2), 100);
			}
				break;

			case 3:
			{
				// Should set the gripper to release mode.
				HAL_UART_Transmit(&huart3,(uint8_t *) str3, sizeof(str3), 100);
			}
				break;

			case 4:
			{
				// Should pause the gripper in its current stage.
				HAL_UART_Transmit(&huart3,(uint8_t *) str4, sizeof(str4), 100);
			}
				break;

			case 5:
			{
				// Should handle recommended motor commands from the Nano.
				HAL_UART_Transmit(&huart3,(uint8_t *) str5, sizeof(str5), 100);
			}
				break;

			default:
			{
				// Should Flush all I2C messages.
				HAL_I2C_Init(&hi2c1);
				HAL_UART_Transmit(&huart3,(uint8_t *) str0, sizeof(str0), 100);
			}
				break;
		}
	}else{
		// Indicate that there was no data in the I2C buffer.
		HAL_UART_Transmit(&huart3,(uint8_t *) strF, sizeof(strF), 10);

		// Have to reset I2C if there was no message available...
		HAL_I2C_Init(&hi2c1);

	}

}

uint32_t I2CTransmitHandle( )
{
	// This function handles the I2C transmition to other controllers.
	// It sends the sensor/motor values and status of the gripper.
	//
	// On success it return the transmition time.
	// On failure it return 0.

	// Transmit struct for Nucleo.
	messageStructFromNucleo messageFormNucleo;

	// Indicate status of I2C transmition.
	int transStatus;

	// Debug messages.
	const char str1[] = "Transmit Success.\n\r";
	const char str2[] = "Transmit Failure.\n\r";
	const char str3[] = "About to transmit.\n\r";

	// Is to debug communication with receiver.
	messageFormNucleo.motorStatus[0] = 1;
	messageFormNucleo.motorStatus[1] = 3;
	messageFormNucleo.motorStatus[2] = 3;
	messageFormNucleo.motorStatus[3] = 7;

	// Indicate that a I2C transimtion is about to happen.
	HAL_UART_Transmit(&huart3,(uint8_t *) str3, sizeof(str1), 150);

	// Need to reset I2C before transmition, don't know why...

	// Transmit the data from Nucleo.
	transStatus = HAL_I2C_Slave_Transmit(&hi2c1,(uint8_t *) &messageFormNucleo, sizeof(messageStructFromNucleo), 100);

	//Print transmit status.
	if(transStatus == 0)
	{
		// Transmit gripper information.
		HAL_UART_Transmit(&huart3,(uint8_t *) str1, sizeof(str1), 50);

		// Toggle orange led to see transmition.
		HAL_GPIO_TogglePin(GPIOE, GPIO_PIN_1);

		// Return the latest transmit time.
		return osKernelGetTickCount();

	}else{

		// Transmit debug message.
		HAL_UART_Transmit(&huart3,(uint8_t *) str2, sizeof(str2), 50);
		// Return error value.
		return 0;
	}

}

/* USER CODE END 4 */

void StartControlTask(void *argument)
{
  /* USER CODE BEGIN 5 */
  /* Infinite loop */
  for(;;)
  {
	HAL_GPIO_TogglePin(GPIOB, GPIO_PIN_0);
	osDelay(2000);
  }

  osThreadTerminate(NULL);

  /* USER CODE END 5 */
}

void StartCommBoard(void *argument)
{
  /* USER CODE BEGIN StartCommBoard */
  /* Infinite loop */

	// Set up time variables.
	const uint32_t deadlineCommunication = 2000;
	const uint32_t communicationSleepTime = 25;
	uint32_t transmitionStatus;
	uint32_t lastTransmitTime = osKernelGetTickCount();

	// Indicate that I2C communication is started.
	const char str0[] = "Starting I2C Communication.\n\r";
	HAL_UART_Transmit(&huart3,(uint8_t *) str0, sizeof(str0), 50);

  for(;;)
  {

	// Check if for new incoming I2C messages.
	// Suspend all other task from interrupt.
	osKernelLock();
	// Handle received I2C data.
	I2CCommandHandle();
	osKernelUnlock();

	// Check if it is time to do a new transmit.
	if( (lastTransmitTime + deadlineCommunication) <= osKernelGetTickCount() )
	{
		// Suspend all other task from interrupt.
		osKernelLock();

		// Transmit data from Nucleo.
		transmitionStatus = I2CTransmitHandle();

		// Check if the data were transmitted.
		if(transmitionStatus != 0)
		{
			lastTransmitTime = transmitionStatus;
		}

		osKernelUnlock();

	}

	// Communication task sleep.
	osDelay(communicationSleepTime);

  }

  osThreadTerminate(NULL);

  /* USER CODE END StartCommBoard */
}

void StartSensorRead(void *argument)
{
  /* USER CODE BEGIN StartSensorRead */

  sensValue sensorPacket;

  startUpMouse();

  /* Infinite loop */
  for(;;)
  {

    // Read the sensor values.
	readMouseSensor( &sensorPacket );

    //UART Send data to console.
    // plotSensorData( &sensorPacket );

    osDelay(1000);

  }

  osThreadTerminate(NULL);

  /* USER CODE END StartSensorRead */
}

void StartSafety(void *argument)
{
  /* USER CODE BEGIN StartSafety */

  /* Infinite loop */
  for(;;)
  {

	HAL_GPIO_TogglePin(GPIOB, GPIO_PIN_14);
	osDelay(1500);

  }

  osThreadTerminate(NULL);

  //status = HAL_SPI_TransmitReceive(&hspi4, &motion[i], &readByte, sizeof(unsigned char), 100);
  //HAL_UART_Transmit(&huart3, &readByte, sizeof(char), 100);
  /* USER CODE END StartSafety */
}

void HAL_TIM_PeriodElapsedCallback(TIM_HandleTypeDef *htim)
{
  if (htim->Instance == TIM6) {
    HAL_IncTick();
  }
}

void Error_Handler(void)
{
}

/************************ (C) COPYRIGHT STMicroelectronics *****END OF FILE****/
